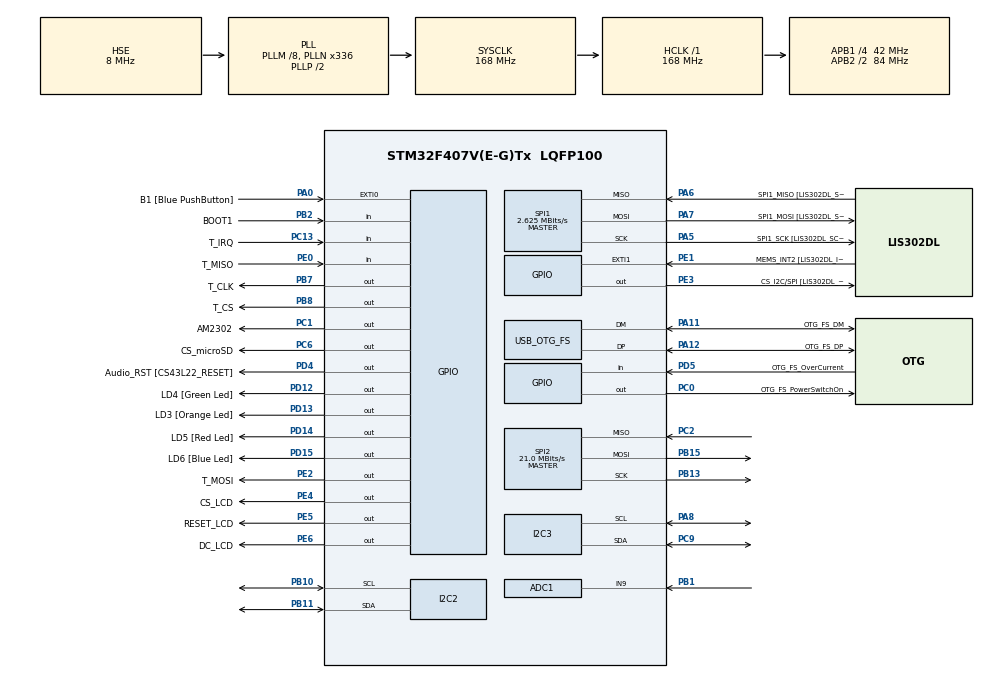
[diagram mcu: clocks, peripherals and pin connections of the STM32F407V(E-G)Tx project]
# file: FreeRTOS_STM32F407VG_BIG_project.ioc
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ADC1.Channel-6\#ChannelRegularConversion=ADC_CHANNEL_9
ADC1.NbrOfConversionFlag=1
ADC1.Rank-6\#ChannelRegularConversion=1
ADC1.SamplingTime-6\#ChannelRegularConversion=ADC_SAMPLETIME_3CYCLES
ADC1.master=1
Dma.Request0=SPI2_TX
Dma.SPI2_TX.0.Direction=DMA_MEMORY_TO_PERIPH
Dma.SPI2_TX.0.FIFOMode=DMA_FIFOMODE_DISABLE
Dma.SPI2_TX.0.Instance=DMA1_Stream4
Dma.SPI2_TX.0.MemDataAlignment=DMA_MDATAALIGN_BYTE
Dma.SPI2_TX.0.MemInc=DMA_MINC_ENABLE
Dma.SPI2_TX.0.Mode=DMA_CIRCULAR
Dma.SPI2_TX.0.PeriphDataAlignment=DMA_PDATAALIGN_BYTE
Dma.SPI2_TX.0.PeriphInc=DMA_PINC_DISABLE
Dma.SPI2_TX.0.Priority=DMA_PRIORITY_LOW
FATFS._CODE_PAGE=850
FATFS._MAX_SS=4096
FATFS._USE_LFN=2
FREERTOS.Queues01=UARTQueue,10,QUEUE_t,0,Static,UARTQueueBuffer,UARTQueueControlBlock;LCDQueue,1,LCDQUEUE,0,Static,LCDQueueBuffer,LCDQueueControlBlock;BME280_Queue,2,BME280QUEUE,0,Static,BME280_QueueBuffer,BME280_QueueControlBlock;MPU6050_Acc_Queue,1,MPU6050ACCQUEUE,0,Static,MPU6050_QueueBuffer,MPU6050_QueueControlBlock;MPU6050_Gyro_Queue,1,MPU6050GYROQUEUE,0,Static,MPU6050_Gyro_QueueBuffer,MPU6050_Gyro_QueueControlBlock;MPU6050_Temp_Queue,1,MPU6050TEMPQUEUE,0,Static,MPU6050_Temp_QueueBuffer,MPU6050_Temp_QueueControlBlock;MS5611_mag_Queue,1,MS5611QUEUE,0,Static,MS5611_mag_QueueBuffer,MS5611_mag_QueueControlBlock;ADC_Queue,3,ADCQUEUE,0,Static,ADC_QueueBuffer,ADC_QueueControlBlock
FREERTOS.Tasks01=defaultTask,24,128,StartDefaultTask,Default,NULL,Static,defaultTaskBuffer,defaultTaskControlBlock;RTC,8,500,Start_RTC,Default,NULL,Static,Blue_LED_BlinkBuffer,Blue_LED_BlinkControlBlock;Show_Resources,8,500,Start_Show_Resources,Default,NULL,Static,Show_ResourcesBuffer,Show_ResourcesControlBlock;UART_Task,8,500,Start_UART_Task,Default,NULL,Static,UART_TaskBuffer,UART_TaskControlBlock;bme280,8,550,Start_bme280,Default,NULL,Static,bme280Buffer,bme280ControlBlock;AM2302,8,500,Start_AM2302,Default,NULL,Static,AM2302Buffer,AM2302ControlBlock;SD_CARD,40,500,Start_SD_CARD,Default,NULL,Static,SD_CARDBuffer,SD_CARDControlBlock;LCD,8,1500,Start_LCD,Default,NULL,Static,LCDBuffer,LCDControlBlock;LCD_touchscreen,8,128,Start_LCD_touchscreen,Default,NULL,Static,LCD_touchscreenBuffer,LCD_touchscreenControlBlock;MPU6050,8,500,Start_MPU6050,Default,NULL,Static,MPU6050Buffer,MPU6050ControlBlock;MS5611,8,256,Start_MS5611,Default,NULL,Static,MS5611Buffer,MS5611ControlBlock;ADC,8,500,Start_ADC,Default,NULL,Static,ADCBuffer,ADCControlBlock
FREERTOS.configGENERATE_RUN_TIME_STATS=1
FREERTOS.configTOTAL_HEAP_SIZE=16000
FREERTOS.configUSE_NEWLIB_REENTRANT=1
FREERTOS.configUSE_STATS_FORMATTING_FUNCTIONS=1
Mcu.Family=STM32F4
Mcu.Name=STM32F407V(E-G)Tx
Mcu.Package=LQFP100
NVIC.DMA1_Stream4_IRQn=true\:5\:0\:true\:false\:true\:true\:false\:true
NVIC.OTG_FS_IRQn=true\:5\:0\:false\:false\:true\:true\:true\:true
NVIC.PriorityGroup=NVIC_PRIORITYGROUP_4
NVIC.SPI2_IRQn=true\:5\:0\:false\:false\:true\:true\:true\:true
NVIC.TIM1_UP_TIM10_IRQn=true\:5\:0\:false\:false\:true\:false\:false\:true
NVIC.TIM2_IRQn=true\:5\:0\:false\:false\:true\:true\:true\:true
NVIC.TIM3_IRQn=true\:5\:0\:false\:false\:true\:true\:true\:true
NVIC.TIM8_TRG_COM_TIM14_IRQn=true\:15\:0\:false\:false\:true\:false\:false\:true
NVIC.TimeBase=TIM8_TRG_COM_TIM14_IRQn
NVIC.TimeBaseIP=TIM14
PA0-WKUP.GPIO_Label=B1 [Blue PushButton]
PA0-WKUP.GPIO_ModeDefaultEXTI=GPIO_MODE_EVT_RISING
PA0-WKUP.GPIO_PuPd=GPIO_NOPULL
PA0-WKUP.Signal=GPXTI0
PA10.GPIO_Label=OTG_FS_ID
PA10.GPIO_Mode=GPIO_MODE_AF_PP
PA10.GPIO_PuPd=GPIO_NOPULL
PA10.GPIO_Speed=GPIO_SPEED_FREQ_LOW
PA10.Signal=USB_OTG_FS_ID
PA11.GPIO_Label=OTG_FS_DM
PA11.GPIO_Mode=GPIO_MODE_AF_PP
PA11.GPIO_PuPd=GPIO_NOPULL
PA11.GPIO_Speed=GPIO_SPEED_FREQ_LOW
PA11.Mode=Device_Only
PA11.Signal=USB_OTG_FS_DM
PA12.GPIO_Label=OTG_FS_DP
PA12.GPIO_Mode=GPIO_MODE_AF_PP
PA12.GPIO_PuPd=GPIO_NOPULL
PA12.GPIO_Speed=GPIO_SPEED_FREQ_LOW
PA12.Mode=Device_Only
PA12.Signal=USB_OTG_FS_DP
PA13.GPIO_Label=SWDIO
PA13.Mode=Serial_Wire
PA13.Signal=SYS_JTMS-SWDIO
PA14.GPIO_Label=SWCLK
PA14.Mode=Serial_Wire
PA14.Signal=SYS_JTCK-SWCLK
PA4.GPIO_Label=I2S3_WS [CS43L22_LRCK]
PA4.GPIO_Mode=GPIO_MODE_AF_PP
PA4.GPIO_PuPd=GPIO_NOPULL
PA4.GPIO_Speed=GPIO_SPEED_FREQ_LOW
PA4.Signal=I2S3_WS
PA5.GPIO_Label=SPI1_SCK [LIS302DL_SCL/SPC]
PA5.GPIO_Mode=GPIO_MODE_AF_PP
PA5.GPIO_PuPd=GPIO_NOPULL
PA5.GPIO_Speed=GPIO_SPEED_FREQ_HIGH
PA5.Mode=Full_Duplex_Master
PA5.Signal=SPI1_SCK
PA6.GPIO_Label=SPI1_MISO [LIS302DL_SDO]
PA6.GPIO_Mode=GPIO_MODE_AF_PP
PA6.GPIO_PuPd=GPIO_NOPULL
PA6.GPIO_Speed=GPIO_SPEED_FREQ_HIGH
PA6.Mode=Full_Duplex_Master
PA6.Signal=SPI1_MISO
PA7.GPIO_Label=SPI1_MOSI [LIS302DL_SDA/SDI/SDO]
PA7.GPIO_Mode=GPIO_MODE_AF_PP
PA7.GPIO_PuPd=GPIO_NOPULL
PA7.GPIO_Speed=GPIO_SPEED_FREQ_HIGH
PA7.Mode=Full_Duplex_Master
PA7.Signal=SPI1_MOSI
PA8.Mode=I2C
PA8.Signal=I2C3_SCL
PA9.GPIO_Label=VBUS_FS
PA9.GPIO_Mode=GPIO_MODE_INPUT
PA9.GPIO_PuPd=GPIO_NOPULL
PA9.Signal=USB_OTG_FS_VBUS
PB1.Signal=ADCx_IN9
PB10.Mode=I2C
PB10.Signal=I2C2_SCL
PB11.Mode=I2C
PB11.Signal=I2C2_SDA
PB13.Mode=Full_Duplex_Master
PB13.Signal=SPI2_SCK
PB15.Mode=Full_Duplex_Master
PB15.Signal=SPI2_MOSI
PB2.GPIO_Label=BOOT1
PB2.GPIO_Mode=GPIO_MODE_INPUT
PB2.GPIO_PuPd=GPIO_NOPULL
PB2.Signal=GPIO_Input
PB3.GPIO_Label=SWO
PB3.Signal=SYS_JTDO-SWO
PB6.GPIO_Label=Audio_SCL [CS43L22_SCL]
PB6.GPIO_Mode=GPIO_MODE_AF_OD
PB6.GPIO_Pu=GPIO_PULLUP
PB6.GPIO_PuPd=GPIO_NOPULL
PB6.GPIO_Speed=GPIO_SPEED_FREQ_LOW
PB6.Signal=I2C1_SCL
PB7.GPIO_Label=T_CLK
PB7.GPIO_Speed=GPIO_SPEED_FREQ_VERY_HIGH
PB7.Signal=GPIO_Output
PB8.GPIO_Label=T_CS
PB8.GPIO_Speed=GPIO_SPEED_FREQ_VERY_HIGH
PB8.Signal=GPIO_Output
PB9.GPIO_Label=Audio_SDA [CS43L22_SDA]
PB9.GPIO_Mode=GPIO_MODE_AF_OD
PB9.GPIO_Pu=GPIO_PULLUP
PB9.GPIO_PuPd=GPIO_NOPULL
PB9.GPIO_Speed=GPIO_SPEED_FREQ_LOW
PB9.Signal=I2C1_SDA
PC0.GPIO_Label=OTG_FS_PowerSwitchOn
PC0.GPIO_PuPd=GPIO_NOPULL
PC0.GPIO_Speed=GPIO_SPEED_FREQ_LOW
PC0.PinState=GPIO_PIN_SET
PC0.Signal=GPIO_Output
PC1.GPIO_Label=AM2302
PC1.Signal=GPIO_Output
PC10.GPIO_Label=I2S3_SCK [CS43L22_SCLK]
PC10.GPIO_Mode=GPIO_MODE_AF_PP
PC10.GPIO_PuPd=GPIO_NOPULL
PC10.GPIO_Speed=GPIO_SPEED_FREQ_LOW
PC10.Signal=I2S3_CK
PC12.GPIO_Label=I2S3_SD [CS43L22_SDIN]
PC12.GPIO_Mode=GPIO_MODE_AF_PP
PC12.GPIO_PuPd=GPIO_NOPULL
PC12.GPIO_Speed=GPIO_SPEED_FREQ_LOW
PC12.Signal=I2S3_SD
PC13-ANTI_TAMP.GPIO_Label=T_IRQ
PC13-ANTI_TAMP.Signal=GPIO_Input
PC14-OSC32_IN.GPIO_Label=PC14-OSC32_IN
PC14-OSC32_IN.Mode=LSE-External-Oscillator
PC14-OSC32_IN.Signal=RCC_OSC32_IN
PC15-OSC32_OUT.GPIO_Label=PC15-OSC32_OUT
PC15-OSC32_OUT.Mode=LSE-External-Oscillator
PC15-OSC32_OUT.Signal=RCC_OSC32_OUT
PC2.Mode=Full_Duplex_Master
PC2.Signal=SPI2_MISO
PC3.GPIO_Label=PDM_OUT [MP45DT02_DOUT]
PC3.GPIO_Mode=GPIO_MODE_AF_PP
PC3.GPIO_PuPd=GPIO_NOPULL
PC3.GPIO_Speed=GPIO_SPEED_FREQ_LOW
PC3.Signal=I2S2_SD
PC6.GPIO_Label=CS_microSD
PC6.GPIO_Speed=GPIO_SPEED_FREQ_HIGH
PC6.Signal=GPIO_Output
PC7.GPIO_Label=I2S3_MCK [CS43L22_MCLK]
PC7.GPIO_Mode=GPIO_MODE_AF_PP
PC7.GPIO_PuPd=GPIO_NOPULL
PC7.GPIO_Speed=GPIO_SPEED_FREQ_LOW
PC7.Signal=I2S3_MCK
PC9.Mode=I2C
PC9.Signal=I2C3_SDA
PD12.GPIO_Label=LD4 [Green Led]
PD12.GPIO_PuPd=GPIO_NOPULL
PD12.GPIO_Speed=GPIO_SPEED_FREQ_LOW
PD12.Signal=GPIO_Output
PD13.GPIO_Label=LD3 [Orange Led]
PD13.GPIO_PuPd=GPIO_NOPULL
PD13.GPIO_Speed=GPIO_SPEED_FREQ_LOW
PD13.Signal=GPIO_Output
PD14.GPIO_Label=LD5 [Red Led]
PD14.GPIO_PuPd=GPIO_NOPULL
PD14.GPIO_Speed=GPIO_SPEED_FREQ_LOW
PD14.Signal=GPIO_Output
PD15.GPIO_Label=LD6 [Blue Led]
PD15.GPIO_PuPd=GPIO_NOPULL
PD15.GPIO_Speed=GPIO_SPEED_FREQ_LOW
PD15.Signal=GPIO_Output
PD4.GPIO_Label=Audio_RST [CS43L22_RESET]
PD4.GPIO_PuPd=GPIO_NOPULL
PD4.GPIO_Speed=GPIO_SPEED_FREQ_LOW
PD4.Signal=GPIO_Output
PD5.GPIO_Label=OTG_FS_OverCurrent
PD5.GPIO_Mode=GPIO_MODE_INPUT
PD5.GPIO_PuPd=GPIO_NOPULL
PD5.Signal=GPIO_Input
PE0.GPIO_Label=T_MISO
PE0.Signal=GPIO_Input
PE1.GPIO_Label=MEMS_INT2 [LIS302DL_INT2]
PE1.GPIO_ModeDefaultEXTI=GPIO_MODE_EVT_RISING
PE1.GPIO_PuPd=GPIO_NOPULL
PE1.Signal=GPXTI1
PE2.GPIO_Label=T_MOSI
PE2.Signal=GPIO_Output
PE3.GPIO_Label=CS_I2C/SPI [LIS302DL_CS_I2C/SPI]
PE3.GPIO_PuPd=GPIO_NOPULL
PE3.GPIO_Speed=GPIO_SPEED_FREQ_LOW
PE3.Signal=GPIO_Output
PE4.GPIO_Label=CS_LCD
PE4.Signal=GPIO_Output
PE5.GPIO_Label=RESET_LCD
PE5.GPIO_Speed=GPIO_SPEED_FREQ_VERY_HIGH
PE5.Signal=GPIO_Output
PE6.GPIO_Label=DC_LCD
PE6.GPIO_Speed=GPIO_SPEED_FREQ_VERY_HIGH
PE6.Signal=GPIO_Output
PH0-OSC_IN.GPIO_Label=PH0-OSC_IN
PH0-OSC_IN.Mode=HSE-External-Oscillator
PH0-OSC_IN.Signal=RCC_OSC_IN
PH1-OSC_OUT.GPIO_Label=PH1-OSC_OUT
PH1-OSC_OUT.Mode=HSE-External-Oscillator
PH1-OSC_OUT.Signal=RCC_OSC_OUT
ProjectManager.HeapSize=0x800
ProjectManager.StackSize=0x900
ProjectManager.TargetToolchain=STM32CubeIDE
RCC.48MHZClocksFreq_Value=48000000
RCC.AHBFreq_Value=168000000
RCC.APB1CLKDivider=RCC_HCLK_DIV4
RCC.APB1Freq_Value=42000000
RCC.APB1TimFreq_Value=84000000
RCC.APB2CLKDivider=RCC_HCLK_DIV2
RCC.APB2Freq_Value=84000000
RCC.APB2TimFreq_Value=168000000
RCC.CortexFreq_Value=168000000
RCC.HCLKFreq_Value=168000000
RCC.HSE_VALUE=8000000
RCC.HSI_VALUE=16000000
RCC.PLLM=8
RCC.PLLN=336
RCC.PLLQ=7
RCC.RCC_RTC_Clock_Source=RCC_RTCCLKSOURCE_LSE
RCC.RCC_RTC_Clock_SourceVirtual=RCC_RTCCLKSOURCE_LSE
RCC.SYSCLKFreq_VALUE=168000000
RCC.SYSCLKSource=RCC_SYSCLKSOURCE_PLLCLK
RCC.VCOOutputFreq_Value=336000000
RTC.Alarm=RTC_ALARM_A
RTC.AlarmDateWeekDaySel=RTC_ALARMDATEWEEKDAYSEL_WEEKDAY
RTC.Date=28
RTC.Hours=23
RTC.Minutes=59
RTC.Month=RTC_MONTH_DECEMBER
RTC.Seconds=45
RTC.Seconds_A=10
RTC.StoreOperation=RTC_STOREOPERATION_RESET
RTC.WeekDay=RTC_WEEKDAY_TUESDAY
SH.ADCx_IN9.0=ADC1_IN9,IN9
SPI1.BaudRatePrescaler=SPI_BAUDRATEPRESCALER_32
SPI1.CalculateBaudRate=2.625 MBits/s
SPI1.Direction=SPI_DIRECTION_2LINES
SPI1.Mode=SPI_MODE_MASTER
SPI1.VirtualType=VM_MASTER
SPI2.CalculateBaudRate=21.0 MBits/s
SPI2.Direction=SPI_DIRECTION_2LINES
SPI2.Mode=SPI_MODE_MASTER
SPI2.VirtualType=VM_MASTER
TIM1.Period=10000
TIM1.Prescaler=16800-1
TIM1.TIM_MasterOutputTrigger=TIM_TRGO_UPDATE
TIM10.AutoReloadPreload=TIM_AUTORELOAD_PRELOAD_ENABLE
TIM10.Period=10-1
TIM10.Prescaler=168-1
TIM2.AutoReloadPreload=TIM_AUTORELOAD_PRELOAD_DISABLE
TIM2.Period=10
TIM2.Prescaler=10
TIM3.AutoReloadPreload=TIM_AUTORELOAD_PRELOAD_ENABLE
TIM3.Period=10
TIM3.Prescaler=839
USB_DEVICE.CLASS_NAME_FS=CDC
USB_DEVICE.VirtualMode-CDC_FS=Cdc
USB_DEVICE.VirtualModeFS=Cdc_FS
USB_OTG_FS.VirtualMode=Device_Only
VP_FATFS_VS_Generic.Mode=User_defined
VP_FREERTOS_VS_CMSIS_V2.Mode=CMSIS_V2
VP_RNG_VS_RNG.Mode=RNG_Activate
VP_RTC_VS_RTC_Activate.Mode=RTC_Enabled
VP_RTC_VS_RTC_Alarm_A_Intern.Mode=Alarm A
VP_RTC_VS_RTC_Calendar.Mode=RTC_Calendar
VP_SYS_VS_tim14.Mode=TIM14
VP_TIM10_VS_ClockSourceINT.Mode=Enable_Timer
VP_TIM1_VS_ClockSourceINT.Mode=Internal
VP_TIM2_VS_ClockSourceINT.Mode=Internal
VP_TIM3_VS_ClockSourceINT.Mode=Internal
VP_USB_DEVICE_VS_USB_DEVICE_CDC_FS.Mode=CDC_FS
board=STM32F407G-DISC1

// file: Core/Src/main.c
/* USER CODE BEGIN Header */
/**
  ******************************************************************************
  * @file           : main.c
  * @brief          : Main program body
  ******************************************************************************
  * @attention
  *
  * <h2><center>&copy; Copyright (c) 2021 STMicroelectronics.
  * All rights reserved.</center></h2>
  *
  * This software component is licensed by ST under Ultimate Liberty license
  * SLA0044, the "License"; You may not use this file except in compliance with
  * the License. You may obtain a copy of the License at:
  *                             www.st.com/SLA0044
  *
  ******************************************************************************
  */
/* USER CODE END Header */
#include "main.h"
#include "cmsis_os.h"
#include "fatfs.h"
#include "usb_device.h"
#include "usb_device.h"

/* USER CODE BEGIN Includes */
#include "string.h"
#include "usbd_cdc_if.h"
#include "task.h"
#include <stdio.h>
#include <stdbool.h>
#include <SD_Card/File_Handling_RTOS.h>

// Sensors
#include "sensors/BME280/bme280_defs.h"
#include "sensors/BME280/bme280.h"

// SD
#include "LCD/spi_ili9341.h"
#include "LCD/ILI9341_Touchscreen.h"

#include "sensors/MEMS/mpu6050.h"

#include "sensors/MEMS/ms5611.h"

/* USER CODE END Includes */

typedef StaticTask_t osStaticThreadDef_t;
typedef StaticQueue_t osStaticMessageQDef_t;
/* USER CODE BEGIN PTD */
typedef struct 							// Queue for UARD
{
	char Buf[1024];
}QUEUE_t;

typedef struct							// Queue for Touch LCD
{
	char buff[100];
}LCDQUEUE;

typedef struct
{
	char bme280_temperature_and_humidity[20];
}BME280QUEUE;

typedef struct
{
	char mpu6050_acc_x_y_z[30];
}MPU6050ACCQUEUE;

typedef struct
{
	char mpu6050_gyro_x_y_z[30];
}MPU6050GYROQUEUE;

typedef struct
{
	char mpu6050_temp[10];
}MPU6050TEMPQUEUE;

typedef struct
{
	char MS5611_mag_x_y_z_temp_and_pressure[30];
}MS5611QUEUE;

typedef struct
{
	char ADC_value_and_voltage[30];
}ADCQUEUE;

volatile unsigned long ulHighFreqebcyTimerTicks;		// This variable using for calculate how many time all tasks was running.
char str_management_memory_str[1000] = {0};
int freemem = 0;

uint32_t tim_val = 0;

// For SD works (use in fatfs_sd.c file)
volatile uint8_t FatFsCnt = 0;
volatile uint8_t Timer1, Timer2;

// LCD //////////////////////////////////
extern uint16_t TFT9341_WIDTH;
extern uint16_t TFT9341_HEIGHT;
// LCD DMA
uint8_t dma_spi_fl=0;
uint32_t dma_spi_cnt=1;
////////////////////////////////////////
// MS5611 sensor P and T
extern uint32_t raw_pressure, raw_temperature;

/* USER CODE END PTD */

ADC_HandleTypeDef hadc1;

I2C_HandleTypeDef hi2c2;
I2C_HandleTypeDef hi2c3;

RNG_HandleTypeDef hrng;

RTC_HandleTypeDef hrtc;

SPI_HandleTypeDef hspi1;
SPI_HandleTypeDef hspi2;
DMA_HandleTypeDef hdma_spi2_tx;

TIM_HandleTypeDef htim1;
TIM_HandleTypeDef htim2;
TIM_HandleTypeDef htim3;
TIM_HandleTypeDef htim10;

/* Definitions for defaultTask */
osThreadId_t defaultTaskHandle;
uint32_t defaultTaskBuffer[ 128 ];
osStaticThreadDef_t defaultTaskControlBlock;
const osThreadAttr_t defaultTask_attributes = {
  .name = "defaultTask",
  .cb_mem = &defaultTaskControlBlock,
  .cb_size = sizeof(defaultTaskControlBlock),
  .stack_mem = &defaultTaskBuffer[0],
  .stack_size = sizeof(defaultTaskBuffer),
  .priority = (osPriority_t) osPriorityNormal,
};
/* Definitions for RTC */
osThreadId_t RTCHandle;
uint32_t Blue_LED_BlinkBuffer[ 500 ];
osStaticThreadDef_t Blue_LED_BlinkControlBlock;
const osThreadAttr_t RTC_attributes = {
  .name = "RTC",
  .cb_mem = &Blue_LED_BlinkControlBlock,
  .cb_size = sizeof(Blue_LED_BlinkControlBlock),
  .stack_mem = &Blue_LED_BlinkBuffer[0],
  .stack_size = sizeof(Blue_LED_BlinkBuffer),
  .priority = (osPriority_t) osPriorityLow,
};
/* Definitions for Show_Resources */
osThreadId_t Show_ResourcesHandle;
uint32_t Show_ResourcesBuffer[ 500 ];
osStaticThreadDef_t Show_ResourcesControlBlock;
const osThreadAttr_t Show_Resources_attributes = {
  .name = "Show_Resources",
  .cb_mem = &Show_ResourcesControlBlock,
  .cb_size = sizeof(Show_ResourcesControlBlock),
  .stack_mem = &Show_ResourcesBuffer[0],
  .stack_size = sizeof(Show_ResourcesBuffer),
  .priority = (osPriority_t) osPriorityLow,
};
/* Definitions for UART_Task */
osThreadId_t UART_TaskHandle;
uint32_t UART_TaskBuffer[ 500 ];
osStaticThreadDef_t UART_TaskControlBlock;
const osThreadAttr_t UART_Task_attributes = {
  .name = "UART_Task",
  .cb_mem = &UART_TaskControlBlock,
  .cb_size = sizeof(UART_TaskControlBlock),
  .stack_mem = &UART_TaskBuffer[0],
  .stack_size = sizeof(UART_TaskBuffer),
  .priority = (osPriority_t) osPriorityLow,
};
/* Definitions for bme280 */
osThreadId_t bme280Handle;
uint32_t bme280Buffer[ 550 ];
osStaticThreadDef_t bme280ControlBlock;
const osThreadAttr_t bme280_attributes = {
  .name = "bme280",
  .cb_mem = &bme280ControlBlock,
  .cb_size = sizeof(bme280ControlBlock),
  .stack_mem = &bme280Buffer[0],
  .stack_size = sizeof(bme280Buffer),
  .priority = (osPriority_t) osPriorityLow,
};
/* Definitions for AM2302 */
osThreadId_t AM2302Handle;
uint32_t AM2302Buffer[ 500 ];
osStaticThreadDef_t AM2302ControlBlock;
const osThreadAttr_t AM2302_attributes = {
  .name = "AM2302",
  .cb_mem = &AM2302ControlBlock,
  .cb_size = sizeof(AM2302ControlBlock),
  .stack_mem = &AM2302Buffer[0],
  .stack_size = sizeof(AM2302Buffer),
  .priority = (osPriority_t) osPriorityLow,
};
/* Definitions for SD_CARD */
osThreadId_t SD_CARDHandle;
uint32_t SD_CARDBuffer[ 500 ];
osStaticThreadDef_t SD_CARDControlBlock;
const osThreadAttr_t SD_CARD_attributes = {
  .name = "SD_CARD",
  .cb_mem = &SD_CARDControlBlock,
  .cb_size = sizeof(SD_CARDControlBlock),
  .stack_mem = &SD_CARDBuffer[0],
  .stack_size = sizeof(SD_CARDBuffer),
  .priority = (osPriority_t) osPriorityHigh,
};
/* Definitions for LCD */
osThreadId_t LCDHandle;
uint32_t LCDBuffer[ 1500 ];
osStaticThreadDef_t LCDControlBlock;
const osThreadAttr_t LCD_attributes = {
  .name = "LCD",
  .cb_mem = &LCDControlBlock,
  .cb_size = sizeof(LCDControlBlock),
  .stack_mem = &LCDBuffer[0],
  .stack_size = sizeof(LCDBuffer),
  .priority = (osPriority_t) osPriorityLow,
};
/* Definitions for LCD_touchscreen */
osThreadId_t LCD_touchscreenHandle;
uint32_t LCD_touchscreenBuffer[ 128 ];
osStaticThreadDef_t LCD_touchscreenControlBlock;
const osThreadAttr_t LCD_touchscreen_attributes = {
  .name = "LCD_touchscreen",
  .cb_mem = &LCD_touchscreenControlBlock,
  .cb_size = sizeof(LCD_touchscreenControlBlock),
  .stack_mem = &LCD_touchscreenBuffer[0],
  .stack_size = sizeof(LCD_touchscreenBuffer),
  .priority = (osPriority_t) osPriorityLow,
};
/* Definitions for MPU6050 */
osThreadId_t MPU6050Handle;
uint32_t MPU6050Buffer[ 500 ];
osStaticThreadDef_t MPU6050ControlBlock;
const osThreadAttr_t MPU6050_attributes = {
  .name = "MPU6050",
  .cb_mem = &MPU6050ControlBlock,
  .cb_size = sizeof(MPU6050ControlBlock),
  .stack_mem = &MPU6050Buffer[0],
  .stack_size = sizeof(MPU6050Buffer),
  .priority = (osPriority_t) osPriorityLow,
};
/* Definitions for MS5611 */
osThreadId_t MS5611Handle;
uint32_t MS5611Buffer[ 256 ];
osStaticThreadDef_t MS5611ControlBlock;
const osThreadAttr_t MS5611_attributes = {
  .name = "MS5611",
  .cb_mem = &MS5611ControlBlock,
  .cb_size = sizeof(MS5611ControlBlock),
  .stack_mem = &MS5611Buffer[0],
  .stack_size = sizeof(MS5611Buffer),
  .priority = (osPriority_t) osPriorityLow,
};
/* Definitions for ADC */
osThreadId_t ADCHandle;
uint32_t ADCBuffer[ 500 ];
osStaticThreadDef_t ADCControlBlock;
const osThreadAttr_t ADC_attributes = {
  .name = "ADC",
  .cb_mem = &ADCControlBlock,
  .cb_size = sizeof(ADCControlBlock),
  .stack_mem = &ADCBuffer[0],
  .stack_size = sizeof(ADCBuffer),
  .priority = (osPriority_t) osPriorityLow,
};
/* Definitions for UARTQueue */
osMessageQueueId_t UARTQueueHandle;
uint8_t UARTQueueBuffer[ 10 * sizeof( QUEUE_t ) ];
osStaticMessageQDef_t UARTQueueControlBlock;
const osMessageQueueAttr_t UARTQueue_attributes = {
  .name = "UARTQueue",
  .cb_mem = &UARTQueueControlBlock,
  .cb_size = sizeof(UARTQueueControlBlock),
  .mq_mem = &UARTQueueBuffer,
  .mq_size = sizeof(UARTQueueBuffer)
};
/* Definitions for LCDQueue */
osMessageQueueId_t LCDQueueHandle;
uint8_t LCDQueueBuffer[ 1 * sizeof( LCDQUEUE ) ];
osStaticMessageQDef_t LCDQueueControlBlock;
const osMessageQueueAttr_t LCDQueue_attributes = {
  .name = "LCDQueue",
  .cb_mem = &LCDQueueControlBlock,
  .cb_size = sizeof(LCDQueueControlBlock),
  .mq_mem = &LCDQueueBuffer,
  .mq_size = sizeof(LCDQueueBuffer)
};
/* Definitions for BME280_Queue */
osMessageQueueId_t BME280_QueueHandle;
uint8_t BME280_QueueBuffer[ 2 * sizeof( BME280QUEUE ) ];
osStaticMessageQDef_t BME280_QueueControlBlock;
const osMessageQueueAttr_t BME280_Queue_attributes = {
  .name = "BME280_Queue",
  .cb_mem = &BME280_QueueControlBlock,
  .cb_size = sizeof(BME280_QueueControlBlock),
  .mq_mem = &BME280_QueueBuffer,
  .mq_size = sizeof(BME280_QueueBuffer)
};
/* Definitions for MPU6050_Acc_Queue */
osMessageQueueId_t MPU6050_Acc_QueueHandle;
uint8_t MPU6050_QueueBuffer[ 1 * sizeof( MPU6050ACCQUEUE ) ];
osStaticMessageQDef_t MPU6050_QueueControlBlock;
const osMessageQueueAttr_t MPU6050_Acc_Queue_attributes = {
  .name = "MPU6050_Acc_Queue",
  .cb_mem = &MPU6050_QueueControlBlock,
  .cb_size = sizeof(MPU6050_QueueControlBlock),
  .mq_mem = &MPU6050_QueueBuffer,
  .mq_size = sizeof(MPU6050_QueueBuffer)
};
/* Definitions for MPU6050_Gyro_Queue */
osMessageQueueId_t MPU6050_Gyro_QueueHandle;
uint8_t MPU6050_Gyro_QueueBuffer[ 1 * sizeof( MPU6050GYROQUEUE ) ];
osStaticMessageQDef_t MPU6050_Gyro_QueueControlBlock;
const osMessageQueueAttr_t MPU6050_Gyro_Queue_attributes = {
  .name = "MPU6050_Gyro_Queue",
  .cb_mem = &MPU6050_Gyro_QueueControlBlock,
  .cb_size = sizeof(MPU6050_Gyro_QueueControlBlock),
  .mq_mem = &MPU6050_Gyro_QueueBuffer,
  .mq_size = sizeof(MPU6050_Gyro_QueueBuffer)
};
/* Definitions for MPU6050_Temp_Queue */
osMessageQueueId_t MPU6050_Temp_QueueHandle;
uint8_t MPU6050_Temp_QueueBuffer[ 1 * sizeof( MPU6050TEMPQUEUE ) ];
osStaticMessageQDef_t MPU6050_Temp_QueueControlBlock;
const osMessageQueueAttr_t MPU6050_Temp_Queue_attributes = {
  .name = "MPU6050_Temp_Queue",
  .cb_mem = &MPU6050_Temp_QueueControlBlock,
  .cb_size = sizeof(MPU6050_Temp_QueueControlBlock),
  .mq_mem = &MPU6050_Temp_QueueBuffer,
  .mq_size = sizeof(MPU6050_Temp_QueueBuffer)
};
/* Definitions for MS5611_mag_Queue */
osMessageQueueId_t MS5611_mag_QueueHandle;
uint8_t MS5611_mag_QueueBuffer[ 1 * sizeof( MS5611QUEUE ) ];
osStaticMessageQDef_t MS5611_mag_QueueControlBlock;
const osMessageQueueAttr_t MS5611_mag_Queue_attributes = {
  .name = "MS5611_mag_Queue",
  .cb_mem = &MS5611_mag_QueueControlBlock,
  .cb_size = sizeof(MS5611_mag_QueueControlBlock),
  .mq_mem = &MS5611_mag_QueueBuffer,
  .mq_size = sizeof(MS5611_mag_QueueBuffer)
};
/* Definitions for ADC_Queue */
osMessageQueueId_t ADC_QueueHandle;
uint8_t ADC_QueueBuffer[ 3 * sizeof( ADCQUEUE ) ];
osStaticMessageQDef_t ADC_QueueControlBlock;
const osMessageQueueAttr_t ADC_Queue_attributes = {
  .name = "ADC_Queue",
  .cb_mem = &ADC_QueueControlBlock,
  .cb_size = sizeof(ADC_QueueControlBlock),
  .mq_mem = &ADC_QueueBuffer,
  .mq_size = sizeof(ADC_QueueBuffer)
};
/* USER CODE BEGIN PV */

// BME280 part /////////////////////////////////////////////////////////////////////////////////////
struct bme280_dev dev;
struct bme280_data comp_data;
int8_t rslt;

int8_t init_bme280(void);
void bme280_measure(void);

//----------------------------------------------------------------------------------------
int8_t user_i2c_read(uint8_t id, uint8_t reg_addr, uint8_t *data, uint16_t len)
{
  if(HAL_I2C_Master_Transmit(&hi2c3, (id << 1), &reg_addr, 1, 10) != HAL_OK) return -1;
  if(HAL_I2C_Master_Receive(&hi2c3, (id << 1) | 0x01, data, len, 10) != HAL_OK) return -1;

  return 0;
}
//----------------------------------------------------------------------------------------
void user_delay_ms(uint32_t period)
{
  HAL_Delay(period);
}
//----------------------------------------------------------------------------------------
int8_t user_i2c_write(uint8_t id, uint8_t reg_addr, uint8_t *data, uint16_t len)
{
  int8_t *buf;
  buf = malloc(len +1);
  buf[0] = reg_addr;
  memcpy(buf +1, data, len);

  if(HAL_I2C_Master_Transmit(&hi2c3, (id << 1), (uint8_t*)buf, len + 1, HAL_MAX_DELAY) != HAL_OK) return -1;

  free(buf);
  return 0;
}
// End BME280 part/////////////////////////////////////////////////////////////////////////////////////

// ---------------------------------------------------------------------------------
// Function for generate dalay more than 10 us (using for AM2302 T and H sensor)
bool delay_us(uint16_t us)
{
	__HAL_TIM_SET_COUNTER(&htim10, 0);
	tim_val = us/10;
	HAL_TIM_Base_Start_IT(&htim10);
	while(tim_val != 0)
	{

	}
	HAL_TIM_Base_Stop_IT(&htim10);
	tim_val = 0;
	int s = 99;
	return true;
}
// ---------------------------------------------------------------------------------
// For DMA SPI2 (LCD)
void HAL_SPI_TxCpltCallback(SPI_HandleTypeDef *hspi)
{
	if(hspi == &hspi2)
	{
	    dma_spi_cnt--;
	    if(dma_spi_cnt==0)
	    {
	    	HAL_SPI_DMAStop(&hspi2);
	    	dma_spi_cnt=1;
	    	dma_spi_fl=1;
	    }
	}
}
// ---------------------------------------------------------------------------------
/* USER CODE END PV */

void SystemClock_Config(void);
static void MX_GPIO_Init(void);
static void MX_TIM3_Init(void);
static void MX_I2C3_Init(void);
static void MX_TIM2_Init(void);
static void MX_TIM10_Init(void);
static void MX_SPI1_Init(void);
static void MX_TIM1_Init(void);
static void MX_RTC_Init(void);
static void MX_SPI2_Init(void);
static void MX_DMA_Init(void);
static void MX_RNG_Init(void);
static void MX_I2C2_Init(void);
static void MX_ADC1_Init(void);
void StartDefaultTask(void *argument);
void Start_RTC(void *argument);
void Start_Show_Resources(void *argument);
void Start_UART_Task(void *argument);
void Start_bme280(void *argument);
void Start_AM2302(void *argument);
void Start_SD_CARD(void *argument);
void Start_LCD(void *argument);
void Start_LCD_touchscreen(void *argument);
void Start_MPU6050(void *argument);
void Start_MS5611(void *argument);
void Start_ADC(void *argument);

int main(void)
{

  /* MCU Configuration--------------------------------------------------------*/

  /* Reset of all peripherals, Initializes the Flash interface and the Systick. */
  HAL_Init();

  /* Configure the system clock */
  SystemClock_Config();

  /* Initialize all configured peripherals */
  MX_GPIO_Init();
  MX_TIM3_Init();
  MX_I2C3_Init();
  MX_TIM2_Init();
  MX_TIM10_Init();
  MX_SPI1_Init();
  MX_FATFS_Init();
  MX_TIM1_Init();
  MX_RTC_Init();
  MX_SPI2_Init();
  MX_DMA_Init();
  MX_RNG_Init();
  MX_I2C2_Init();
  MX_ADC1_Init();
  /* USER CODE BEGIN 2 */
  HAL_TIM_Base_Start_IT(&htim3);		//  This TIM3 using for calculate how many time all tasks was running.

  //HAL_TIM_Base_Start_IT(&htim2);
  //HAL_TIM_Base_Start_IT(&htim10);			// Using for generate us delays
  HAL_TIM_Base_Start_IT(&htim1);			// Blink Green LED

  /* IF LCD DOESN'T WORK !
  RIGHT IN RIGHT ORDER SPI2 AND DMA !!!!
  MX_DMA_Init();
  MX_SPI2_Init();
  */
  HAL_DMA_DeInit(&hdma_spi2_tx);
  HAL_SPI_DeInit(&hspi2);
  MX_DMA_Init();
  MX_SPI2_Init();

  /* USER CODE END 2 */

  /* Init scheduler */
  osKernelInitialize();

  /* Create the queue(s) */
  /* creation of UARTQueue */
  UARTQueueHandle = osMessageQueueNew (10, sizeof(QUEUE_t), &UARTQueue_attributes);

  /* creation of LCDQueue */
  LCDQueueHandle = osMessageQueueNew (1, sizeof(LCDQUEUE), &LCDQueue_attributes);

  /* creation of BME280_Queue */
  BME280_QueueHandle = osMessageQueueNew (2, sizeof(BME280QUEUE), &BME280_Queue_attributes);

  /* creation of MPU6050_Acc_Queue */
  MPU6050_Acc_QueueHandle = osMessageQueueNew (1, sizeof(MPU6050ACCQUEUE), &MPU6050_Acc_Queue_attributes);

  /* creation of MPU6050_Gyro_Queue */
  MPU6050_Gyro_QueueHandle = osMessageQueueNew (1, sizeof(MPU6050GYROQUEUE), &MPU6050_Gyro_Queue_attributes);

  /* creation of MPU6050_Temp_Queue */
  MPU6050_Temp_QueueHandle = osMessageQueueNew (1, sizeof(MPU6050TEMPQUEUE), &MPU6050_Temp_Queue_attributes);

  /* creation of MS5611_mag_Queue */
  MS5611_mag_QueueHandle = osMessageQueueNew (1, sizeof(MS5611QUEUE), &MS5611_mag_Queue_attributes);

  /* creation of ADC_Queue */
  ADC_QueueHandle = osMessageQueueNew (3, sizeof(ADCQUEUE), &ADC_Queue_attributes);

  /* Create the thread(s) */
  /* creation of defaultTask */
  defaultTaskHandle = osThreadNew(StartDefaultTask, NULL, &defaultTask_attributes);

  /* creation of RTC */
  RTCHandle = osThreadNew(Start_RTC, NULL, &RTC_attributes);

  /* creation of Show_Resources */
  Show_ResourcesHandle = osThreadNew(Start_Show_Resources, NULL, &Show_Resources_attributes);

  /* creation of UART_Task */
  UART_TaskHandle = osThreadNew(Start_UART_Task, NULL, &UART_Task_attributes);

  /* creation of bme280 */
  bme280Handle = osThreadNew(Start_bme280, NULL, &bme280_attributes);

  /* creation of AM2302 */
  AM2302Handle = osThreadNew(Start_AM2302, NULL, &AM2302_attributes);

  /* creation of SD_CARD */
  SD_CARDHandle = osThreadNew(Start_SD_CARD, NULL, &SD_CARD_attributes);

  /* creation of LCD */
  LCDHandle = osThreadNew(Start_LCD, NULL, &LCD_attributes);

  /* creation of LCD_touchscreen */
  LCD_touchscreenHandle = osThreadNew(Start_LCD_touchscreen, NULL, &LCD_touchscreen_attributes);

  /* creation of MPU6050 */
  MPU6050Handle = osThreadNew(Start_MPU6050, NULL, &MPU6050_attributes);

  /* creation of MS5611 */
  MS5611Handle = osThreadNew(Start_MS5611, NULL, &MS5611_attributes);

  /* creation of ADC */
  ADCHandle = osThreadNew(Start_ADC, NULL, &ADC_attributes);

  /* Start scheduler */
  osKernelStart();

  /* We should never get here as control is now taken by the scheduler */
  /* Infinite loop */
  while (1)
  {

  }
}

void SystemClock_Config(void)
{
  RCC_OscInitTypeDef RCC_OscInitStruct = {0};
  RCC_ClkInitTypeDef RCC_ClkInitStruct = {0};

  /** Configure the main internal regulator output voltage
  */
  __HAL_RCC_PWR_CLK_ENABLE();
  __HAL_PWR_VOLTAGESCALING_CONFIG(PWR_REGULATOR_VOLTAGE_SCALE1);
  /** Initializes the RCC Oscillators according to the specified parameters
  * in the RCC_OscInitTypeDef structure.
  */
  RCC_OscInitStruct.OscillatorType = RCC_OSCILLATORTYPE_HSE|RCC_OSCILLATORTYPE_LSE;
  RCC_OscInitStruct.HSEState = RCC_HSE_ON;
  RCC_OscInitStruct.LSEState = RCC_LSE_ON;
  RCC_OscInitStruct.PLL.PLLState = RCC_PLL_ON;
  RCC_OscInitStruct.PLL.PLLSource = RCC_PLLSOURCE_HSE;
  RCC_OscInitStruct.PLL.PLLM = 8;
  RCC_OscInitStruct.PLL.PLLN = 336;
  RCC_OscInitStruct.PLL.PLLP = RCC_PLLP_DIV2;
  RCC_OscInitStruct.PLL.PLLQ = 7;
  if (HAL_RCC_OscConfig(&RCC_OscInitStruct) != HAL_OK)
  {
    Error_Handler();
  }
  /** Initializes the CPU, AHB and APB buses clocks
  */
  RCC_ClkInitStruct.ClockType = RCC_CLOCKTYPE_HCLK|RCC_CLOCKTYPE_SYSCLK
                              |RCC_CLOCKTYPE_PCLK1|RCC_CLOCKTYPE_PCLK2;
  RCC_ClkInitStruct.SYSCLKSource = RCC_SYSCLKSOURCE_PLLCLK;
  RCC_ClkInitStruct.AHBCLKDivider = RCC_SYSCLK_DIV1;
  RCC_ClkInitStruct.APB1CLKDivider = RCC_HCLK_DIV4;
  RCC_ClkInitStruct.APB2CLKDivider = RCC_HCLK_DIV2;

  if (HAL_RCC_ClockConfig(&RCC_ClkInitStruct, FLASH_LATENCY_5) != HAL_OK)
  {
    Error_Handler();
  }
}

static void MX_ADC1_Init(void)
{

  ADC_ChannelConfTypeDef sConfig = {0};

  /** Configure the global features of the ADC (Clock, Resolution, Data Alignment and number of conversion)
  */
  hadc1.Instance = ADC1;
  hadc1.Init.ClockPrescaler = ADC_CLOCK_SYNC_PCLK_DIV4;
  hadc1.Init.Resolution = ADC_RESOLUTION_12B;
  hadc1.Init.ScanConvMode = DISABLE;
  hadc1.Init.ContinuousConvMode = DISABLE;
  hadc1.Init.DiscontinuousConvMode = DISABLE;
  hadc1.Init.ExternalTrigConvEdge = ADC_EXTERNALTRIGCONVEDGE_NONE;
  hadc1.Init.ExternalTrigConv = ADC_SOFTWARE_START;
  hadc1.Init.DataAlign = ADC_DATAALIGN_RIGHT;
  hadc1.Init.NbrOfConversion = 1;
  hadc1.Init.DMAContinuousRequests = DISABLE;
  hadc1.Init.EOCSelection = ADC_EOC_SINGLE_CONV;
  if (HAL_ADC_Init(&hadc1) != HAL_OK)
  {
    Error_Handler();
  }
  /** Configure for the selected ADC regular channel its corresponding rank in the sequencer and its sample time.
  */
  sConfig.Channel = ADC_CHANNEL_9;
  sConfig.Rank = 1;
  sConfig.SamplingTime = ADC_SAMPLETIME_3CYCLES;
  if (HAL_ADC_ConfigChannel(&hadc1, &sConfig) != HAL_OK)
  {
    Error_Handler();
  }

}

static void MX_I2C2_Init(void)
{

  hi2c2.Instance = I2C2;
  hi2c2.Init.ClockSpeed = 100000;
  hi2c2.Init.DutyCycle = I2C_DUTYCYCLE_2;
  hi2c2.Init.OwnAddress1 = 0;
  hi2c2.Init.AddressingMode = I2C_ADDRESSINGMODE_7BIT;
  hi2c2.Init.DualAddressMode = I2C_DUALADDRESS_DISABLE;
  hi2c2.Init.OwnAddress2 = 0;
  hi2c2.Init.GeneralCallMode = I2C_GENERALCALL_DISABLE;
  hi2c2.Init.NoStretchMode = I2C_NOSTRETCH_DISABLE;
  if (HAL_I2C_Init(&hi2c2) != HAL_OK)
  {
    Error_Handler();
  }

}

static void MX_I2C3_Init(void)
{

  hi2c3.Instance = I2C3;
  hi2c3.Init.ClockSpeed = 100000;
  hi2c3.Init.DutyCycle = I2C_DUTYCYCLE_2;
  hi2c3.Init.OwnAddress1 = 0;
  hi2c3.Init.AddressingMode = I2C_ADDRESSINGMODE_7BIT;
  hi2c3.Init.DualAddressMode = I2C_DUALADDRESS_DISABLE;
  hi2c3.Init.OwnAddress2 = 0;
  hi2c3.Init.GeneralCallMode = I2C_GENERALCALL_DISABLE;
  hi2c3.Init.NoStretchMode = I2C_NOSTRETCH_DISABLE;
  if (HAL_I2C_Init(&hi2c3) != HAL_OK)
  {
    Error_Handler();
  }

}

static void MX_RNG_Init(void)
{

  hrng.Instance = RNG;
  if (HAL_RNG_Init(&hrng) != HAL_OK)
  {
    Error_Handler();
  }

}

static void MX_RTC_Init(void)
{

  RTC_TimeTypeDef sTime = {0};
  RTC_DateTypeDef sDate = {0};
  RTC_AlarmTypeDef sAlarm = {0};

  /** Initialize RTC Only
  */
  hrtc.Instance = RTC;
  hrtc.Init.HourFormat = RTC_HOURFORMAT_24;
  hrtc.Init.AsynchPrediv = 127;
  hrtc.Init.SynchPrediv = 255;
  hrtc.Init.OutPut = RTC_OUTPUT_DISABLE;
  hrtc.Init.OutPutPolarity = RTC_OUTPUT_POLARITY_HIGH;
  hrtc.Init.OutPutType = RTC_OUTPUT_TYPE_OPENDRAIN;
  if (HAL_RTC_Init(&hrtc) != HAL_OK)
  {
    Error_Handler();
  }

  /** Initialize RTC and set the Time and Date
  */
  sTime.Hours = 0x23;
  sTime.Minutes = 0x59;
  sTime.Seconds = 0x45;
  sTime.DayLightSaving = RTC_DAYLIGHTSAVING_NONE;
  sTime.StoreOperation = RTC_STOREOPERATION_RESET;
  if (HAL_RTC_SetTime(&hrtc, &sTime, RTC_FORMAT_BCD) != HAL_OK)
  {
    Error_Handler();
  }
  sDate.WeekDay = RTC_WEEKDAY_TUESDAY;
  sDate.Month = RTC_MONTH_DECEMBER;
  sDate.Date = 0x28;
  sDate.Year = 0x0;

  if (HAL_RTC_SetDate(&hrtc, &sDate, RTC_FORMAT_BCD) != HAL_OK)
  {
    Error_Handler();
  }
  /** Enable the Alarm A
  */
  sAlarm.AlarmTime.Hours = 0x0;
  sAlarm.AlarmTime.Minutes = 0x0;
  sAlarm.AlarmTime.Seconds = 0x10;
  sAlarm.AlarmTime.SubSeconds = 0x0;
  sAlarm.AlarmTime.DayLightSaving = RTC_DAYLIGHTSAVING_NONE;
  sAlarm.AlarmTime.StoreOperation = RTC_STOREOPERATION_RESET;
  sAlarm.AlarmMask = RTC_ALARMMASK_NONE;
  sAlarm.AlarmSubSecondMask = RTC_ALARMSUBSECONDMASK_ALL;
  sAlarm.AlarmDateWeekDaySel = RTC_ALARMDATEWEEKDAYSEL_WEEKDAY;
  sAlarm.AlarmDateWeekDay = RTC_WEEKDAY_MONDAY;
  sAlarm.Alarm = RTC_ALARM_A;
  if (HAL_RTC_SetAlarm(&hrtc, &sAlarm, RTC_FORMAT_BCD) != HAL_OK)
  {
    Error_Handler();
  }

}

static void MX_SPI1_Init(void)
{

  /* SPI1 parameter configuration*/
  hspi1.Instance = SPI1;
  hspi1.Init.Mode = SPI_MODE_MASTER;
  hspi1.Init.Direction = SPI_DIRECTION_2LINES;
  hspi1.Init.DataSize = SPI_DATASIZE_8BIT;
  hspi1.Init.CLKPolarity = SPI_POLARITY_LOW;
  hspi1.Init.CLKPhase = SPI_PHASE_1EDGE;
  hspi1.Init.NSS = SPI_NSS_SOFT;
  hspi1.Init.BaudRatePrescaler = SPI_BAUDRATEPRESCALER_32;
  hspi1.Init.FirstBit = SPI_FIRSTBIT_MSB;
  hspi1.Init.TIMode = SPI_TIMODE_DISABLE;
  hspi1.Init.CRCCalculation = SPI_CRCCALCULATION_DISABLE;
  hspi1.Init.CRCPolynomial = 10;
  if (HAL_SPI_Init(&hspi1) != HAL_OK)
  {
    Error_Handler();
  }

}

static void MX_SPI2_Init(void)
{

  /* SPI2 parameter configuration*/
  hspi2.Instance = SPI2;
  hspi2.Init.Mode = SPI_MODE_MASTER;
  hspi2.Init.Direction = SPI_DIRECTION_2LINES;
  hspi2.Init.DataSize = SPI_DATASIZE_8BIT;
  hspi2.Init.CLKPolarity = SPI_POLARITY_LOW;
  hspi2.Init.CLKPhase = SPI_PHASE_1EDGE;
  hspi2.Init.NSS = SPI_NSS_SOFT;
  hspi2.Init.BaudRatePrescaler = SPI_BAUDRATEPRESCALER_2;
  hspi2.Init.FirstBit = SPI_FIRSTBIT_MSB;
  hspi2.Init.TIMode = SPI_TIMODE_DISABLE;
  hspi2.Init.CRCCalculation = SPI_CRCCALCULATION_DISABLE;
  hspi2.Init.CRCPolynomial = 10;
  if (HAL_SPI_Init(&hspi2) != HAL_OK)
  {
    Error_Handler();
  }

}

static void MX_TIM1_Init(void)
{

  TIM_ClockConfigTypeDef sClockSourceConfig = {0};
  TIM_MasterConfigTypeDef sMasterConfig = {0};

  htim1.Instance = TIM1;
  htim1.Init.Prescaler = 16800-1;
  htim1.Init.CounterMode = TIM_COUNTERMODE_UP;
  htim1.Init.Period = 10000;
  htim1.Init.ClockDivision = TIM_CLOCKDIVISION_DIV1;
  htim1.Init.RepetitionCounter = 0;
  htim1.Init.AutoReloadPreload = TIM_AUTORELOAD_PRELOAD_DISABLE;
  if (HAL_TIM_Base_Init(&htim1) != HAL_OK)
  {
    Error_Handler();
  }
  sClockSourceConfig.ClockSource = TIM_CLOCKSOURCE_INTERNAL;
  if (HAL_TIM_ConfigClockSource(&htim1, &sClockSourceConfig) != HAL_OK)
  {
    Error_Handler();
  }
  sMasterConfig.MasterOutputTrigger = TIM_TRGO_UPDATE;
  sMasterConfig.MasterSlaveMode = TIM_MASTERSLAVEMODE_DISABLE;
  if (HAL_TIMEx_MasterConfigSynchronization(&htim1, &sMasterConfig) != HAL_OK)
  {
    Error_Handler();
  }

}

static void MX_TIM2_Init(void)
{

  TIM_ClockConfigTypeDef sClockSourceConfig = {0};
  TIM_MasterConfigTypeDef sMasterConfig = {0};

  htim2.Instance = TIM2;
  htim2.Init.Prescaler = 10;
  htim2.Init.CounterMode = TIM_COUNTERMODE_UP;
  htim2.Init.Period = 10;
  htim2.Init.ClockDivision = TIM_CLOCKDIVISION_DIV1;
  htim2.Init.AutoReloadPreload = TIM_AUTORELOAD_PRELOAD_DISABLE;
  if (HAL_TIM_Base_Init(&htim2) != HAL_OK)
  {
    Error_Handler();
  }
  sClockSourceConfig.ClockSource = TIM_CLOCKSOURCE_INTERNAL;
  if (HAL_TIM_ConfigClockSource(&htim2, &sClockSourceConfig) != HAL_OK)
  {
    Error_Handler();
  }
  sMasterConfig.MasterOutputTrigger = TIM_TRGO_RESET;
  sMasterConfig.MasterSlaveMode = TIM_MASTERSLAVEMODE_DISABLE;
  if (HAL_TIMEx_MasterConfigSynchronization(&htim2, &sMasterConfig) != HAL_OK)
  {
    Error_Handler();
  }

}

static void MX_TIM3_Init(void)
{

  TIM_ClockConfigTypeDef sClockSourceConfig = {0};
  TIM_MasterConfigTypeDef sMasterConfig = {0};

  htim3.Instance = TIM3;
  htim3.Init.Prescaler = 839;
  htim3.Init.CounterMode = TIM_COUNTERMODE_UP;
  htim3.Init.Period = 10;
  htim3.Init.ClockDivision = TIM_CLOCKDIVISION_DIV1;
  htim3.Init.AutoReloadPreload = TIM_AUTORELOAD_PRELOAD_ENABLE;
  if (HAL_TIM_Base_Init(&htim3) != HAL_OK)
  {
    Error_Handler();
  }
  sClockSourceConfig.ClockSource = TIM_CLOCKSOURCE_INTERNAL;
  if (HAL_TIM_ConfigClockSource(&htim3, &sClockSourceConfig) != HAL_OK)
  {
    Error_Handler();
  }
  sMasterConfig.MasterOutputTrigger = TIM_TRGO_RESET;
  sMasterConfig.MasterSlaveMode = TIM_MASTERSLAVEMODE_DISABLE;
  if (HAL_TIMEx_MasterConfigSynchronization(&htim3, &sMasterConfig) != HAL_OK)
  {
    Error_Handler();
  }

}

static void MX_TIM10_Init(void)
{

  htim10.Instance = TIM10;
  htim10.Init.Prescaler = 168-1;
  htim10.Init.CounterMode = TIM_COUNTERMODE_UP;
  htim10.Init.Period = 10-1;
  htim10.Init.ClockDivision = TIM_CLOCKDIVISION_DIV1;
  htim10.Init.AutoReloadPreload = TIM_AUTORELOAD_PRELOAD_ENABLE;
  if (HAL_TIM_Base_Init(&htim10) != HAL_OK)
  {
    Error_Handler();
  }

}

static void MX_DMA_Init(void)
{

  /* DMA controller clock enable */
  __HAL_RCC_DMA1_CLK_ENABLE();

  /* DMA interrupt init */
  /* DMA1_Stream4_IRQn interrupt configuration */
  HAL_NVIC_SetPriority(DMA1_Stream4_IRQn, 5, 0);
  HAL_NVIC_EnableIRQ(DMA1_Stream4_IRQn);

}

static void MX_GPIO_Init(void)
{
  GPIO_InitTypeDef GPIO_InitStruct = {0};

  /* GPIO Ports Clock Enable */
  __HAL_RCC_GPIOE_CLK_ENABLE();
  __HAL_RCC_GPIOC_CLK_ENABLE();
  __HAL_RCC_GPIOH_CLK_ENABLE();
  __HAL_RCC_GPIOA_CLK_ENABLE();
  __HAL_RCC_GPIOB_CLK_ENABLE();
  __HAL_RCC_GPIOD_CLK_ENABLE();

  /*Configure GPIO pin Output Level */
  HAL_GPIO_WritePin(GPIOE, T_MOSI_Pin|CS_I2C_SPI_Pin|CS_LCD_Pin|RESET_LCD_Pin
                          |DC_LCD_Pin, GPIO_PIN_RESET);

  /*Configure GPIO pin Output Level */
  HAL_GPIO_WritePin(OTG_FS_PowerSwitchOn_GPIO_Port, OTG_FS_PowerSwitchOn_Pin, GPIO_PIN_SET);

  /*Configure GPIO pin Output Level */
  HAL_GPIO_WritePin(GPIOC, AM2302_Pin|CS_microSD_Pin, GPIO_PIN_RESET);

  /*Configure GPIO pin Output Level */
  HAL_GPIO_WritePin(GPIOD, LD4_Pin|LD3_Pin|LD5_Pin|LD6_Pin
                          |Audio_RST_Pin, GPIO_PIN_RESET);

  /*Configure GPIO pin Output Level */
  HAL_GPIO_WritePin(GPIOB, T_CLK_Pin|T_CS_Pin, GPIO_PIN_RESET);

  /*Configure GPIO pins : T_MOSI_Pin CS_I2C_SPI_Pin CS_LCD_Pin */
  GPIO_InitStruct.Pin = T_MOSI_Pin|CS_I2C_SPI_Pin|CS_LCD_Pin;
  GPIO_InitStruct.Mode = GPIO_MODE_OUTPUT_PP;
  GPIO_InitStruct.Pull = GPIO_NOPULL;
  GPIO_InitStruct.Speed = GPIO_SPEED_FREQ_LOW;
  HAL_GPIO_Init(GPIOE, &GPIO_InitStruct);

  /*Configure GPIO pins : RESET_LCD_Pin DC_LCD_Pin */
  GPIO_InitStruct.Pin = RESET_LCD_Pin|DC_LCD_Pin;
  GPIO_InitStruct.Mode = GPIO_MODE_OUTPUT_PP;
  GPIO_InitStruct.Pull = GPIO_NOPULL;
  GPIO_InitStruct.Speed = GPIO_SPEED_FREQ_VERY_HIGH;
  HAL_GPIO_Init(GPIOE, &GPIO_InitStruct);

  /*Configure GPIO pin : T_IRQ_Pin */
  GPIO_InitStruct.Pin = T_IRQ_Pin;
  GPIO_InitStruct.Mode = GPIO_MODE_INPUT;
  GPIO_InitStruct.Pull = GPIO_NOPULL;
  HAL_GPIO_Init(T_IRQ_GPIO_Port, &GPIO_InitStruct);

  /*Configure GPIO pins : OTG_FS_PowerSwitchOn_Pin AM2302_Pin */
  GPIO_InitStruct.Pin = OTG_FS_PowerSwitchOn_Pin|AM2302_Pin;
  GPIO_InitStruct.Mode = GPIO_MODE_OUTPUT_PP;
  GPIO_InitStruct.Pull = GPIO_NOPULL;
  GPIO_InitStruct.Speed = GPIO_SPEED_FREQ_LOW;
  HAL_GPIO_Init(GPIOC, &GPIO_InitStruct);

  /*Configure GPIO pin : PDM_OUT_Pin */
  GPIO_InitStruct.Pin = PDM_OUT_Pin;
  GPIO_InitStruct.Mode = GPIO_MODE_AF_PP;
  GPIO_InitStruct.Pull = GPIO_NOPULL;
  GPIO_InitStruct.Speed = GPIO_SPEED_FREQ_LOW;
  GPIO_InitStruct.Alternate = GPIO_AF5_SPI2;
  HAL_GPIO_Init(PDM_OUT_GPIO_Port, &GPIO_InitStruct);

  /*Configure GPIO pin : B1_Pin */
  GPIO_InitStruct.Pin = B1_Pin;
  GPIO_InitStruct.Mode = GPIO_MODE_EVT_RISING;
  GPIO_InitStruct.Pull = GPIO_NOPULL;
  HAL_GPIO_Init(B1_GPIO_Port, &GPIO_InitStruct);

  /*Configure GPIO pin : I2S3_WS_Pin */
  GPIO_InitStruct.Pin = I2S3_WS_Pin;
  GPIO_InitStruct.Mode = GPIO_MODE_AF_PP;
  GPIO_InitStruct.Pull = GPIO_NOPULL;
  GPIO_InitStruct.Speed = GPIO_SPEED_FREQ_LOW;
  GPIO_InitStruct.Alternate = GPIO_AF6_SPI3;
  HAL_GPIO_Init(I2S3_WS_GPIO_Port, &GPIO_InitStruct);

  /*Configure GPIO pin : BOOT1_Pin */
  GPIO_InitStruct.Pin = BOOT1_Pin;
  GPIO_InitStruct.Mode = GPIO_MODE_INPUT;
  GPIO_InitStruct.Pull = GPIO_NOPULL;
  HAL_GPIO_Init(BOOT1_GPIO_Port, &GPIO_InitStruct);

  /*Configure GPIO pins : LD4_Pin LD3_Pin LD5_Pin LD6_Pin
                           Audio_RST_Pin */
  GPIO_InitStruct.Pin = LD4_Pin|LD3_Pin|LD5_Pin|LD6_Pin
                          |Audio_RST_Pin;
  GPIO_InitStruct.Mode = GPIO_MODE_OUTPUT_PP;
  GPIO_InitStruct.Pull = GPIO_NOPULL;
  GPIO_InitStruct.Speed = GPIO_SPEED_FREQ_LOW;
  HAL_GPIO_Init(GPIOD, &GPIO_InitStruct);

  /*Configure GPIO pin : CS_microSD_Pin */
  GPIO_InitStruct.Pin = CS_microSD_Pin;
  GPIO_InitStruct.Mode = GPIO_MODE_OUTPUT_PP;
  GPIO_InitStruct.Pull = GPIO_NOPULL;
  GPIO_InitStruct.Speed = GPIO_SPEED_FREQ_HIGH;
  HAL_GPIO_Init(CS_microSD_GPIO_Port, &GPIO_InitStruct);

  /*Configure GPIO pins : I2S3_MCK_Pin I2S3_SCK_Pin I2S3_SD_Pin */
  GPIO_InitStruct.Pin = I2S3_MCK_Pin|I2S3_SCK_Pin|I2S3_SD_Pin;
  GPIO_InitStruct.Mode = GPIO_MODE_AF_PP;
  GPIO_InitStruct.Pull = GPIO_NOPULL;
  GPIO_InitStruct.Speed = GPIO_SPEED_FREQ_LOW;
  GPIO_InitStruct.Alternate = GPIO_AF6_SPI3;
  HAL_GPIO_Init(GPIOC, &GPIO_InitStruct);

  /*Configure GPIO pin : OTG_FS_OverCurrent_Pin */
  GPIO_InitStruct.Pin = OTG_FS_OverCurrent_Pin;
  GPIO_InitStruct.Mode = GPIO_MODE_INPUT;
  GPIO_InitStruct.Pull = GPIO_NOPULL;
  HAL_GPIO_Init(OTG_FS_OverCurrent_GPIO_Port, &GPIO_InitStruct);

  /*Configure GPIO pins : Audio_SCL_Pin Audio_SDA_Pin */
  GPIO_InitStruct.Pin = Audio_SCL_Pin|Audio_SDA_Pin;
  GPIO_InitStruct.Mode = GPIO_MODE_AF_OD;
  GPIO_InitStruct.Pull = GPIO_PULLUP;
  GPIO_InitStruct.Speed = GPIO_SPEED_FREQ_LOW;
  GPIO_InitStruct.Alternate = GPIO_AF4_I2C1;
  HAL_GPIO_Init(GPIOB, &GPIO_InitStruct);

  /*Configure GPIO pins : T_CLK_Pin T_CS_Pin */
  GPIO_InitStruct.Pin = T_CLK_Pin|T_CS_Pin;
  GPIO_InitStruct.Mode = GPIO_MODE_OUTPUT_PP;
  GPIO_InitStruct.Pull = GPIO_NOPULL;
  GPIO_InitStruct.Speed = GPIO_SPEED_FREQ_VERY_HIGH;
  HAL_GPIO_Init(GPIOB, &GPIO_InitStruct);

  /*Configure GPIO pin : T_MISO_Pin */
  GPIO_InitStruct.Pin = T_MISO_Pin;
  GPIO_InitStruct.Mode = GPIO_MODE_INPUT;
  GPIO_InitStruct.Pull = GPIO_NOPULL;
  HAL_GPIO_Init(T_MISO_GPIO_Port, &GPIO_InitStruct);

  /*Configure GPIO pin : MEMS_INT2_Pin */
  GPIO_InitStruct.Pin = MEMS_INT2_Pin;
  GPIO_InitStruct.Mode = GPIO_MODE_EVT_RISING;
  GPIO_InitStruct.Pull = GPIO_NOPULL;
  HAL_GPIO_Init(MEMS_INT2_GPIO_Port, &GPIO_InitStruct);

}

void StartDefaultTask(void *argument)
{
  /* init code for USB_DEVICE */
  MX_USB_DEVICE_Init();
  /* USER CODE BEGIN 5 */
  /* Infinite loop */
  for(;;)
  {
	  osDelay(10);
  }
  /* USER CODE END 5 */
}

void Start_RTC(void *argument)
{
  /* USER CODE BEGIN Start_RTC */
  /* Infinite loop */
	// Task every seconds blink blue LED and send data in virtual com port.
		// Set up RTC
		/*	README <<<<<<<<<<<<<<<<<<<<<<<<<<<<<<
		 * STM32IDE  automatically generated setup code and fill in RTC structure fields seconds, minutes,
		 * hours and date. So, for avoid rewriting time, you need comment automated generated code.
		 *
		 * RTC needs BATTERY for count time when external power will be removed.
		 * For STM32F407 discovery dev board needs remove R26, and connect battery to VBAT (near R26).
		 * Also, need solder the LF Crystal and two capacitors.
		 */

		// 1. Set time
		  RTC_TimeTypeDef sTime = {0};
	//	  sTime.Hours = 9;
	//	  sTime.Minutes = 33;
	//	  sTime.Seconds = 00;
	//	  HAL_RTC_SetTime(&hrtc, &sTime, RTC_FORMAT_BIN);
		  // Set date

		  RTC_DateTypeDef sDate = {0};
	//	  sDate.Date = 29;
	//	  sDate.Month = RTC_MONTH_DECEMBER;
	//	  sDate.WeekDay = RTC_WEEKDAY_WEDNESDAY;
	//	  sDate.Year = 21;
	//	  HAL_RTC_SetDate(&hrtc, &sDate, RTC_FORMAT_BIN);
		  /////////////////////////////////////////////////////////////////////

	QUEUE_t msg;												// Make a queue

	char buff[50] = {0};
	char buf[5] = {0};
	char str_end_of_line[4] = {'\r','\n','\0'};

	static uint8_t i = 1;
	for(;;)
	{
		// Blue LED blink//
		HAL_GPIO_WritePin(GPIOD, LD6_Pin, GPIO_PIN_SET);
		osDelay(100);
		HAL_GPIO_WritePin(GPIOD, LD6_Pin, GPIO_PIN_RESET);
		osDelay(900);

		// RTC part
		HAL_RTC_GetTime(&hrtc, &sTime, RTC_FORMAT_BIN);						// Get time (write in sDime struct)
		HAL_RTC_GetDate(&hrtc, &sDate, RTC_FORMAT_BIN);						// Get data (write in sDime struct)

		memset(msg.Buf, 0, sizeof(msg.Buf));								// Fill in buff '\0'
		memset(buff, 0, sizeof(buff));

		strcat(msg.Buf, "RTC DATA AND TIME >>>>>>>    " );

		// Date
		itoa(sDate.Year, buf, 10);
		strcat(msg.Buf, buf);

		itoa(sDate.Month, buf, 10);
		strcat(msg.Buf, "-");
		strcat(msg.Buf, buf);

		itoa(sDate.Date, buf, 10);
		strcat(msg.Buf, "-");
		strcat(msg.Buf, buf);

		strcat(msg.Buf, " | ");

		// Time
		itoa(sTime.Hours, buf, 10);
		strcat(msg.Buf, buf);

		itoa(sTime.Minutes, buf, 10);
		strcat(msg.Buf, ":");
		strcat(msg.Buf, buf);

		itoa(sTime.Seconds, buf, 10);
		strcat(msg.Buf, ":");
		strcat(msg.Buf, buf);

		strcat(msg.Buf, str_end_of_line);
		osMessageQueuePut(UARTQueueHandle, &msg, 0, osWaitForever);					// Write data on queue (In will print on StartUART_Task task)
	}
  /* USER CODE END Start_RTC */
}

void Start_Show_Resources(void *argument)
{
  /* USER CODE BEGIN Start_Show_Resources */
  /* Infinite loop */
  for(;;)
  {
	  osDelay(5000);												// Every 5 second task management will print data

	  char str_end_of_line[3] = {'\r','\n'};
	  char str_sig = '-';
	  char buff[10] = {0};

	  QUEUE_t msg;												// Make a queue
	  memset(msg.Buf, 0, sizeof(msg.Buf));						// Fill in buff '\0'
	  strcat(msg.Buf, ">>>>> Free heap memory: ");				// Add string to another (Total heap)

	  freemem = xPortGetFreeHeapSize();							// Function return how many free memory.
	  itoa(freemem, buff, 10);
	  strcat(msg.Buf, buff);
	  strcat(msg.Buf, str_end_of_line);

	  // add a hat
	  strcat(msg.Buf, "| TASK NAME  | STATUS | PRIOR | STACK | NUM |\n\r\0");

	  vTaskList(str_management_memory_str);						// Fill in str_management_memory_str array management task information

	  // Finding the  end of string
	  uint16_t buffer_size = 0;
	  while(msg.Buf[buffer_size] != '\0')
	  {
	  	buffer_size ++;
	  }

	  // Add str_management_memory_str to queue string
	  int i = 0;
	  for(i = 0; str_management_memory_str[i] != '\0'; i++)
	  {
	  	// add data to queue
	  	msg.Buf[buffer_size + i] = str_management_memory_str[i];
	  }

	  // add a hat
	  char str_line[] = {"-----------------------\n\r"};
	  char str_head_2[] = {"| TASK NAME | ABS TIME | TASK TIME% |\n\r"};
	  strcat(msg.Buf, str_line);
	  strcat(msg.Buf, str_head_2);

	  memset(str_management_memory_str, 0, sizeof(str_management_memory_str));	// Clean buffer

	  vTaskGetRunTimeStats(str_management_memory_str);							// Function return how much time all functions running.

	  buffer_size = buffer_size + i + (sizeof(str_line)-1) + (sizeof(str_head_2)-1);
	  for(i = 0; str_management_memory_str[i] != '\0'; i++)
	  {
	  	// add data to queue
	  	msg.Buf[buffer_size + i] = str_management_memory_str[i];
	  }
	  strcat(msg.Buf, "#########################################\n\r");

	  osMessageQueuePut(UARTQueueHandle, &msg, 0, osWaitForever);					// Write data on queue (In will print on StartUART_Task task)
  }
  /* USER CODE END Start_Show_Resources */
}

void Start_UART_Task(void *argument)
{
  /* USER CODE BEGIN Start_UART_Task */
  /* Infinite loop */
  QUEUE_t msg;
  for(;;)
  {
	// osMessageQueueGet waiting data on a queue (If data are in queue so print it)
	osMessageQueueGet(UARTQueueHandle, &msg, 0, osWaitForever);			// Write for data on queue
	// Counting how many characters will be transmitted
	uint16_t buffer_size = 0;
	while(msg.Buf[buffer_size] != '\0')
	{
		buffer_size ++;
	}
	// Transmit over virtual comport
	CDC_Transmit_FS(msg.Buf, buffer_size);						// Transmit data over virtual comport
    osDelay(1);
  }
  /* USER CODE END Start_UART_Task */
}

void Start_bme280(void *argument)
{
  /* USER CODE BEGIN Start_bme280 */
  /* Infinite loop */

	//QUEUE_t msg;												// Make a queue

	BME280QUEUE bme280_meg;
	//memset(msg.Buf, 0, sizeof(msg.Buf));						// Fill in buff '\0'

	uint16_t STATUS=0;
	uint16_t addres_device = 0x76;  		 	// BME280
	uint16_t id_addr = 0xD0;
	uint8_t id = 96;							// in hex form
	uint8_t buff=0;        						// Return 0x96 -> Dec 60

	// For debug
	STATUS = HAL_I2C_Mem_Read(&hi2c3, addres_device<<1, id_addr, 1, &buff, 1, 1000);
	if((buff == id) && (STATUS == 0))
	{
		// BME280 founded
	}
	else
	{
		// Error !!! BME280 didn't found
	}

	// Init BME280
	dev.dev_id = BME280_I2C_ADDR_PRIM;
	dev.intf = BME280_I2C_INTF;
	dev.read = user_i2c_read;
	dev.write = user_i2c_write;
	dev.delay_ms = user_delay_ms;

	rslt = bme280_init(&dev);

	dev.settings.osr_h = BME280_OVERSAMPLING_1X;
	dev.settings.osr_p = BME280_OVERSAMPLING_16X;
	dev.settings.osr_t = BME280_OVERSAMPLING_2X;
	dev.settings.filter = BME280_FILTER_COEFF_16;
	rslt = bme280_set_sensor_settings(BME280_OSR_PRESS_SEL | BME280_OSR_TEMP_SEL | BME280_OSR_HUM_SEL | BME280_FILTER_SEL, &dev);

	rslt = bme280_set_sensor_mode(BME280_NORMAL_MODE, &dev);

	dev.delay_ms(40);

  for(;;)
  {
	  osDelay(1000);

	  char str_t_h_and_p[60] = {0};
	  char str_thp_buffer[12] = {0};

	//  memset(msg.Buf, 0, sizeof(msg.Buf));								// Fill in buff '\0'
	  memset(bme280_meg.bme280_temperature_and_humidity, 0, sizeof(bme280_meg.bme280_temperature_and_humidity));								// Fill in buff '\0'

	  rslt = bme280_get_sensor_data(BME280_ALL, &comp_data, &dev);		// Get data from sensor

	  if(rslt == BME280_OK)
	  {
	  		// Save data variables
	  		int BME280_temperature = comp_data.temperature;
	  		int BME280_humidity = comp_data.humidity;
	  		int BME280_preasure = comp_data.pressure;

	  		// Write T, H and P in str_t_h_and_p buffer
	  		// Write TEMPERATURE
//	  		strcat(str_t_h_and_p, "      BME280: \n\r");
	  		strcat(str_t_h_and_p, "T");
	  		sprintf(str_thp_buffer, "%d", BME280_temperature);
	  		strcat(str_t_h_and_p, str_thp_buffer);
	  		strcat(str_t_h_and_p, "C ");

	  		// Write HUMIDYTY
	  		// memset(str_thp_buffer, 0, sizeof(str_thp_buffer));
	  		strcat(str_t_h_and_p, "H");
	  		sprintf(str_thp_buffer, "%d", BME280_humidity);
	  		strcat(str_t_h_and_p, str_thp_buffer);
	  		strcat(str_t_h_and_p, "% ");

	  		// Write PRERASURE
	  		//memset(str_thp_buffer, 0, sizeof(str_thp_buffer));
	  		strcat(str_t_h_and_p, "P");
	  		sprintf(str_thp_buffer, "%d", BME280_preasure);
	  		strcat(str_t_h_and_p, str_thp_buffer);
	  		//strcat(str_t_h_and_p, " mm\n\r\0");

//	  		strcat(msg.Buf, str_t_h_and_p);										//	Write main buffer with data in queue
//	  		osMessageQueuePut(UARTQueueHandle, &msg, 0, osWaitForever);			// Write data on queue (In will print on StartUART_Task task)

	  		strcat(bme280_meg.bme280_temperature_and_humidity, str_t_h_and_p);
	  		osMessageQueuePut(BME280_QueueHandle, &bme280_meg, 0, osWaitForever);
	  }
	  else
	  {
		  strcat(str_t_h_and_p, "ERROR!!!");
		  osMessageQueuePut(BME280_QueueHandle, &bme280_meg, 0, osWaitForever);			// Write data on queue (In will print on StartUART_Task task)

//		  strcat(bme280_meg.bme280_temperature_and_humidity, "ERROR");
//		  osMessageQueuePut(BME280_QueueHandle, &bme280_meg, 0, osWaitForever);
	  }

  }
  /* USER CODE END Start_bme280 */
}

void Start_AM2302(void *argument)
{
  /* USER CODE BEGIN Start_AM2302 */
  /* Infinite loop */
	QUEUE_t msg;												// Make a queue
	memset(msg.Buf, 0, sizeof(msg.Buf));						// Fill in buff '\0'

	GPIOC->MODER |= GPIO_MODER_MODER1_0;            // Output mode GPIOC0
	GPIOC->OTYPER &= ~GPIO_OTYPER_OT_1;             // Push-pull mode
	GPIOC->OSPEEDR |= GPIO_OSPEEDER_OSPEEDR0_1;     // Speed
	GPIOC->ODR ^= 0x02; 							// set GPIOC pin 1 on high
	osDelay(2000);									// First init must be 2 seconds delay

  for(;;)
  {
	  osDelay(3500);			// Measure every 3 seconds
	  //----------------------------------------------------------------------------------------
	  /*
	   * Function make us delay
	   */
//	  __STATIC_INLINE void DelayMicro(__IO uint32_t micros)
//	  {
//	  	uint32_t test_micros = SystemCoreClock;
//	  	micros *= (SystemCoreClock / 100000) /84;
//	  	while (micros--);
//	  }

	  	//  function must use less than one time per 2-3 seconds.
	  /* Init work with sensor:
	   *
	   * From microcontroller
	   * 						            From sensor
	   * 	   Low 10 msec	      High 39 us|	80us Pull down     80us Pull up 	Start Receive data from sensor
	   * ____                     _______	|					 __________________
	   * 	   \	   	           /	   \|					/				   \
	   * 	   	\_________________/			\__________________/		 			\_______
	   *
	   * Receive '0' Bit
	   *     Low 50 us    High 26 - 28 us
	   * __                ___________
	   * 	 \			    /			\
	   * 	  \____________/			 \_
	   *
	   * Receive '1' Bit
	   *     Low 50 us             High 70 us
	   * __                ________________________
	   * 	 \			    /				         \
	   * 	  \____________/			              \_
	   */

	  	bool get_data_status = false;
	  	int j = 0;   							// Counter bytes
	  	int i = 0;								// Counter bits
	  	uint8_t data[4] = {0};					// Buffer for incoming data from sensor
	  	float temper, hum;						// Buffer variables

	  	// Init GPIO like output
	  	GPIOC->MODER |= GPIO_MODER_MODER1_0;            // Output mode GPIOC0
	  	GPIOC->OTYPER &= ~GPIO_OTYPER_OT_1;             // Push-pull mode
	  	GPIOC->OSPEEDR |= GPIO_OSPEEDER_OSPEEDR0_1;     // Speed

	  	GPIOC->ODR &= ~0x02;		// Low level
	  	osDelay(18);
	  	GPIOC->ODR ^= 0x02;			// High level
	  	delay_us(40);

	  	// Make input pin C1
	  	GPIOC->MODER &= ~0x04;  	// Set Pin C1 Input   (MODER GPIOC_1 Must be 00)
	  	GPIOC->PUPDR &= ~0x04;		// Set Pin C1 Pull up

	  	if(GPIOC->IDR & GPIO_IDR_ID1)		// Sensor must pull down
	  	{
	  		get_data_status = false; 					// Error. Sensor not response
	  	}
	  	else
	  	{
	  		get_data_status = true;
	  	}

	  	delay_us(80);

	  	if(!(GPIOC->IDR & GPIO_IDR_ID1))  	// Sensor must pull up
	  	{
	  		get_data_status = false; 					// Error. Sensor not response
	  	}
	  	else
	  	{
	  		get_data_status = true;
	  	}
	  	delay_us(80);

	  	if(get_data_status == true)
	  	{
	  		for(j = 0; j <5; j++)							// Reading 5 bytes
	  		{
	  			data[4-j] = 0;
	  			for(i = 0; i < 8; i++)						// Reading 8 bits
	  			{
	  				while(!(GPIOC->IDR & GPIO_IDR_ID1));	// While signal is "0"
	  				delay_us(30);
	  				if(GPIOC->IDR & GPIO_IDR_ID1)			// If signal is high when wrute "1" in buffer (data[])
	  				{
	  					data[4-j] |= (1 << (7 - i));        // Shift received bite
	  				}
	  				while(GPIOC->IDR & GPIO_IDR_ID1);		// Wait end of "1" signal
	  			}
	  			get_data_status = true;										// Data was been written okay
	  		}

	  		temper = (float)((*(uint16_t*)(data+1)) & 0x3FFF) /10;
	  		if((*(uint16_t*)(data+1)) & 0x8000) temper  *= -1.0;
	  		hum = (float)(*(int16_t*)(data+3)) / 10;

	  		// Write data in queue
	  		char str_t_and_h[60] = {0};
	  		char str_t_and_h_buffer[12] = {0};

	  		memset(msg.Buf, 0, sizeof(msg.Buf));								// Fill in buff '\0'

	  		// Write T and  H P in str_t_h buffer
	  		// Write TEMPERATURE
	  		strcat(str_t_and_h, "     AM2302: \n\r");
	  		strcat(str_t_and_h, "T: ");
	  		sprintf(str_t_and_h_buffer, "%f", temper);
	  		strcat(str_t_and_h, str_t_and_h_buffer);
	  		strcat(str_t_and_h, " C\n\r");

	  		// Write HUMIDYTY
	  		memset(str_t_and_h_buffer, 0, sizeof(str_t_and_h_buffer));

	  		strcat(str_t_and_h, "H: ");
	  		sprintf(str_t_and_h_buffer, "%f", hum);
	  		strcat(str_t_and_h, str_t_and_h_buffer);
	  		strcat(str_t_and_h, " C\n\r\0");

	  		strcat(msg.Buf, str_t_and_h);										//	Write main buffer with data in queue

	  		osMessageQueuePut(UARTQueueHandle, &msg, 0, osWaitForever);			// Write data on queue (In will print on StartUART_Task task)
	  	}
	  	else
	  	{

	  		//i2c_device.AM2302_ready_status = false;
	  	}
  }

  /* USER CODE END Start_AM2302 */
}

void Start_SD_CARD(void *argument)
{
  /* USER CODE BEGIN Start_SD_CARD */
  /* Infinite loop */

	osDelay(1000);
	Mount_SD("/");

	Create_File("test_data_1.txt");
	Update_File("test_data_1.txt","\n\rStart recording\r\n");	// Add data to the end of file

	// Create folders
	Create_Dir("test_folder_1");
	Create_Dir("test_folder_2");
	Create_Dir("test_folder_3");

	Unmount_SD("/");

	static int i = 0;											// Test data for write

  for(;;)
  {
	  // Log data ewery one second
	  osDelay(1000);
	  HAL_GPIO_WritePin(GPIOD, LD3_Pin, GPIO_PIN_SET);			// LED ON

	  Mount_SD("/");

	  char data[10] = {0};
	  sprintf(data, "%d\n", i);
	  Update_File("test_data_1.txt", data);						// Add data to the end of file
	  i++;

	  Unmount_SD("/");

	  HAL_GPIO_WritePin(GPIOD, LD3_Pin, GPIO_PIN_RESET);		// LED OFF
  }
  /* USER CODE END Start_SD_CARD */
}

void Start_LCD(void *argument)
{
  /* USER CODE BEGIN Start_LCD */
  /* Infinite loop */
	BME280QUEUE bme280_meg;
	MPU6050ACCQUEUE mpu6050_acc_meg;
	MPU6050GYROQUEUE mpu6050_gyro_meg;
	MPU6050TEMPQUEUE mpu6050_temperature_meg;
	MS5611QUEUE ms6050_temperature_and_pressure_meg;
	ADCQUEUE adc_meg;

	// Init LCD
	TFT9341_ini(240, 320);
	TFT9341_SetRotation(3);
	TFT9341_SetTextColor(TFT9341_WHITE);
	TFT9341_SetBackColor(TFT9341_BLUE);
	TFT9341_FillScreen(TFT9341_BLUE);

	// Init names sensors
	TFT9341_String_DMA(2,30, "1.RTC ");
	TFT9341_String_DMA(2,45, "2.AM2302");
	TFT9341_String_DMA(2,60, "3.BME280");
	TFT9341_String_DMA(2,75, "4.MPU6050a");
	TFT9341_String_DMA(2,90, "5.MPU6050g");
	TFT9341_String_DMA(2,105, "6.MPU6050t");
	TFT9341_String_DMA(2,120, "7.L883");
	TFT9341_String_DMA(2,135, "8.MS5611");
	TFT9341_String_DMA(2,150, "8.APDS9960");
	TFT9341_String_DMA(2,165, "9.ADC");

	for(;;)
	{
		// Waiting on BME280 data in queue
		osMessageQueueGet(BME280_QueueHandle, &bme280_meg, 0, osWaitForever);
		TFT9341_String(120, 60, bme280_meg.bme280_temperature_and_humidity);

		// Waiting on MPU6050 Acc data in queue
		osMessageQueueGet(MPU6050_Acc_QueueHandle, &mpu6050_acc_meg, 0, osWaitForever);
		TFT9341_String_DMA(120,75, mpu6050_acc_meg.mpu6050_acc_x_y_z);

		// Waiting on MPU6050 Gyro data in queue
		osMessageQueueGet(MPU6050_Gyro_QueueHandle, &mpu6050_gyro_meg, 0, osWaitForever);   // ??????
		TFT9341_String_DMA(120,90, mpu6050_gyro_meg.mpu6050_gyro_x_y_z);
		if(mpu6050_gyro_meg.mpu6050_gyro_x_y_z[2] != '\0')
		{
			int gggggg =  9999;
		}

		// Waiting on MPU6050 Temperature data in queue
		osMessageQueueGet(MPU6050_Temp_QueueHandle, &mpu6050_temperature_meg, 0, osWaitForever);
		TFT9341_String_DMA(120,105, mpu6050_temperature_meg.mpu6050_temp);

		// Waiting on MS5611 temperature and pressure data in queue
		osMessageQueueGet(MS5611_mag_QueueHandle, &ms6050_temperature_and_pressure_meg, 0, osWaitForever);
		TFT9341_String_DMA(120,135, ms6050_temperature_and_pressure_meg.MS5611_mag_x_y_z_temp_and_pressure);

//		char ADC_value_and_voltage[30];
//		}ADCQUEUE;

		// ADC_QueueHandle
		// Waiting on MS5611 temperature and pressure data in queue

//		osMessageQueueGet(ADC_QueueHandle, &adc_meg, 0, osWaitForever);
//		TFT9341_String_DMA(120,165, adc_meg.ADC_value_and_voltage);

		osDelay(1000);
  }
  /* USER CODE END Start_LCD */
}

void Start_LCD_touchscreen(void *argument)
{
  /* USER CODE BEGIN Start_LCD_touchscreen */
  /* Infinite loop */
	LCDQUEUE msg;												// Make QUEUE
	memset(msg.buff, 0, sizeof(msg.buff));						// Fill in buff '\0'
	char buffer[50] = {0};

	for(;;)
  	 {
	  memset(msg.buff, 0, sizeof(msg.buff));						// Fill in buff '\0'
	  //СЕНСОР ЕКРАНУ
	  if(TP_Touchpad_Pressed() == TOUCHPAD_PRESSED)
	  {
		  strcat(buffer, "PRESED ");

		  uint16_t x_and_y[2] = {0};
		  uint8_t status_ts = TP_Read_Coordinates(x_and_y);
		  if(status_ts == TOUCHPAD_DATA_OK)
		  {
			  // Convert coordinate from uint16_t format in string format
			  // And save it in main buffer
			  char buff_x_coordinates[6] = {0};
			  char buff_y_coordinates[6] = {0};
			  char buff_coordinates[15] = {0};

			  strcat(buff_x_coordinates, "x: ");
			  itoa(x_and_y[0], buff_x_coordinates, 10);
			  strcat(buff_x_coordinates, " ");

			  strcat(buff_y_coordinates, "y: ");
			  itoa(x_and_y[1], buff_y_coordinates, 10);
			  strcat(buff_y_coordinates, " ");

			  strcat(buff_coordinates, buff_x_coordinates);
			  strcat(buff_coordinates, buff_y_coordinates);
			  strcat(buffer, buff_coordinates);
		  }
	  }
	  else
	  {
		  strcat(buffer, "NO PRESS                  ");
	  }

	  strcat(msg.buff, buffer);
	  osMessageQueuePut(LCDQueueHandle, &msg, 0, osWaitForever);  	// Write data on queue (In will print on StartUART_Task task)
	  memset(buffer, 0, sizeof(buffer));

	  osDelay(200);
    //osDelay(1);
  }
  /* USER CODE END Start_LCD_touchscreen */
}

void Start_MPU6050(void *argument)
{
  /* USER CODE BEGIN Start_MPU6050 */
  /* Infinite loop */
  MPU6050_t MPU6050;

  MPU6050ACCQUEUE msg_acc;
  MPU6050GYROQUEUE msg_gyro;
  MPU6050TEMPQUEUE msg_temp;

	//char mpu6050_gyro_x_y_z[30];

  char mpu6050_acc[20] = {0};
  char mpu6050_gyro[20] = {0};
  char mpu6050_temp[10] = {0};

  osDelay(500);

  MPU6050_Init(&hi2c2);
  osDelay(500);

  //uint8_t pissition = 0;

  for(;;)
  {
	  int i = 0;
	  uint8_t start_pissition = 1;
	  char mpu6050_buf[10] = {0};
	  memset(msg_acc.mpu6050_acc_x_y_z, 0, sizeof(msg_acc.mpu6050_acc_x_y_z));
	  memset(msg_gyro.mpu6050_gyro_x_y_z, 0, sizeof(msg_gyro.mpu6050_gyro_x_y_z));
	  memset(msg_temp.mpu6050_temp, 0, sizeof(msg_temp.mpu6050_temp));

	  MPU6050_Read_All(&hi2c2, &MPU6050);					// Writr data in MPU6050 struct

	  ////////////////// ACCELERATION
	  // X
	  sprintf(mpu6050_buf ,"%f" ,MPU6050.Ax);
	  strcat(mpu6050_acc, "X");
	  // Read only first digits
	  i = 0;
	  uint8_t j = 0;
	  do{
		  i++;
	  }while(mpu6050_acc[i] != '\0');

	  do{
		  mpu6050_acc[i] = mpu6050_buf[j];
		  i++;
		  j++;
	  }while(j <= 3);										// Read only first digits
	  memset(mpu6050_buf, 0, sizeof(mpu6050_buf));

	  // Y
	  sprintf(mpu6050_buf ,"%f" ,MPU6050.Ay);
	  strcat(mpu6050_acc, " Y");
	  // findings end of string
	  i = 0;
	  do{
		  i++;
	  }while(mpu6050_acc[i] != '\0');

	  j = 0;
	  do{
		  mpu6050_acc[i] = mpu6050_buf[j];
		  i++;
		  j++;
	  }while(j<=3);											// Read only first digits
	  memset(mpu6050_buf, 0, sizeof(mpu6050_buf));

	  // Z
	  sprintf(mpu6050_buf ,"%f" ,MPU6050.Az);
	  strcat(mpu6050_acc, " Z");
	  // findings end of string
	  i = 0;
	  do{
		  i++;
	  }while(mpu6050_acc[i] != '\0');

	  j = 0;
	  do{
	  	mpu6050_acc[i] = mpu6050_buf[j];
	  	i++;
	  	j++;
	  }while(j<=3);											// Read only first digits
	  memset(mpu6050_buf, 0, sizeof(mpu6050_buf));

	  // Write in the acc queue
	  strcat(msg_acc.mpu6050_acc_x_y_z, mpu6050_acc);
	  memset(mpu6050_acc, 0, sizeof(mpu6050_acc));
	  osMessageQueuePut(MPU6050_Acc_QueueHandle, &msg_acc, 0, osWaitForever);

	  ////////////////// GYRO
	  memset(mpu6050_gyro, 0, sizeof(mpu6050_gyro));
	  // X
	  sprintf(mpu6050_buf ,"%f" ,MPU6050.Gx);
	  strcat(mpu6050_gyro, "X");
	  // Read only first digits
	  i = 0;
	  j = 0;
	  do{
		  i++;
	  }while(mpu6050_gyro[i] != '\0');

	  do{
		 mpu6050_gyro[i] = mpu6050_buf[j];
	  	 i++;
	  	 j++;
	  }while(j <= 3);										// Read only first digits
	  memset(mpu6050_buf, 0, sizeof(mpu6050_buf));

	  // Y
	  sprintf(mpu6050_buf ,"%f" ,MPU6050.Gy);
	  strcat(mpu6050_gyro, " Y");
	  // findings end of string
	  i = 0;
	  do{
		  i++;
	  }while(mpu6050_gyro[i] != '\0');

	  j = 0;
	  do{
		  mpu6050_gyro[i] = mpu6050_buf[j];
		  i++;
		  j++;
	  }while(j<=3);											// Read only first digits
	  memset(mpu6050_buf, 0, sizeof(mpu6050_buf));

	  // Z
	  sprintf(mpu6050_buf ,"%f" ,MPU6050.Gz);
	  strcat(mpu6050_gyro, " Z");
	  // findings end of string
	  i = 0;
	  do{
		  i++;
	  }while(mpu6050_gyro[i] != '\0');

	  j = 0;
	  do{
		  mpu6050_gyro[i] = mpu6050_buf[j];
		  i++;
	  	  j++;
	  }while(j<=3);											// Read only first digits
	  memset(mpu6050_buf, 0, sizeof(mpu6050_buf));

		if(mpu6050_gyro[2] != '\0')
		{
			int gggggg =  9999;
		}

	  // Write in the acc queue
	  strcat(msg_gyro.mpu6050_gyro_x_y_z, mpu6050_gyro);
	  memset(mpu6050_gyro, 0, sizeof(mpu6050_gyro));

	  if(msg_gyro.mpu6050_gyro_x_y_z[2] != '\0')
	  {
	  			int gggggg =  9999;
	  }
	  osMessageQueuePut(MPU6050_Gyro_QueueHandle, &msg_gyro, 0, osWaitForever);

	  ////////////////// TEMPERATURE
	  sprintf(mpu6050_buf ,"%f" ,MPU6050.Temperature);
	  strcat(mpu6050_temp, "T ");
	  // Read only first digits
	  i = 0;
	  do{
	 	i++;
	  }while(mpu6050_temp[i] != '\0');

	  j = 0;
	  do{
		  mpu6050_temp[i] = mpu6050_buf[j];
	 	  i++;
	 	  j++;
	  }while(j <= 4);										// Read only first digits
	  memset(mpu6050_buf, 0, sizeof(mpu6050_buf));

	  // Write in the acc queue
	  strcat(msg_temp.mpu6050_temp, mpu6050_temp);
	  memset(mpu6050_temp, 0, sizeof(mpu6050_temp));
	  osMessageQueuePut(MPU6050_Temp_QueueHandle, &msg_temp, 0, osWaitForever);

      osDelay(1000);
  }
  /* USER CODE END Start_MPU6050 */
}

void Start_MS5611(void *argument)
{
  /* USER CODE BEGIN Start_MS5611 */
  /* Infinite loop */
	MS5611QUEUE msg_mag;

	osDelay(500);
	//ms5611_init();

	for(;;)
	{
//		ms5611_init();
		//osDelay(100);

		double temperature = 0;
		double pressure = 0;
		char ms5611_buf[30] = {0};
		char buff[20] = {0};
		uint8_t i = 0;
		memset(msg_mag.MS5611_mag_x_y_z_temp_and_pressure, 0, sizeof(msg_mag.MS5611_mag_x_y_z_temp_and_pressure));

		// Measure T and P from MS5611 sensor
		ms5611_init();
		ms5611_update();

		strcat(ms5611_buf, "T:");

		// Get data
		temperature = ms5611_get_temperature();
		pressure = ms5611_get_pressure();
		pressure = (pressure*100) / 133.3;		// Convert

		// Add temperature data in string
		sprintf(buff, "%0.1f", temperature);
		i = 0;
		do{
			i++;
		}while(ms5611_buf[i] != '\0');

		uint8_t j = 0;
		do
		{
			ms5611_buf[i] = buff[j];
			i++;
			j++;
		}while(j <= 5);
		memset(buff, 0, sizeof(buff));
		//strcat(ms5611_buf, " C");

		// Add pressure data in string
		strcat(ms5611_buf, " P:");
		sprintf(buff, "%.0f", pressure);
		i = 0;
		do{
			i++;
		}while(ms5611_buf[i] != '\0');

		j = 0;
		do
		{
			ms5611_buf[i] = buff[j];
			i++;
			j++;
		}while(buff[j] != '\0');				// Read all digits
		memset(buff, 0, sizeof(buff));
		strcat(ms5611_buf, " mm  ");

		// Write in the queue
		strcat(msg_mag.MS5611_mag_x_y_z_temp_and_pressure, ms5611_buf);
		memset(ms5611_buf, 0, sizeof(ms5611_buf));
		osMessageQueuePut(MS5611_mag_QueueHandle, &msg_mag, 0, osWaitForever);

		osDelay(500);
  }
  /* USER CODE END Start_MS5611 */
}

void Start_ADC(void *argument)
{
  /* USER CODE BEGIN Start_ADC */
  /* Infinite loop */
	//osDelay(2000);

	ADCQUEUE msg;

	HAL_ADC_Start(&hadc1);

  for(;;)
  {
	  char adc_buff[30] = {0};
	  char adc_buff_2[10] = {0};
	  memset(msg.ADC_value_and_voltage, 0, sizeof(msg.ADC_value_and_voltage));

	  HAL_ADC_Start(&hadc1);
	  HAL_ADC_PollForConversion(&hadc1, 100);
	  uint32_t adc_data = HAL_ADC_GetValue(&hadc1);
	  // Convert in voltage
	  float adc_voltage = adc_data*(3.3/4096);
	  HAL_ADC_Stop(&hadc1);

	  sprintf(adc_buff,"%d",adc_data);
	  strcat(adc_buff, "  ");
	  sprintf(adc_buff_2,"%.4f",adc_voltage);
	  strcat(adc_buff, adc_buff_2);
	  strcat(adc_buff, " V");

	  // Write in the queue
	  strcat(msg.ADC_value_and_voltage, adc_buff);
	  memset(adc_buff, 0, sizeof(adc_buff));
	  memset(adc_buff_2, 0, sizeof(adc_buff_2));
	  //osMessageQueuePut(ADCHandle , &msg, 0, osWaitForever);

	  osDelay(1000);
  }
  /* USER CODE END Start_ADC */
}

void HAL_TIM_PeriodElapsedCallback(TIM_HandleTypeDef *htim)
{
  /* USER CODE BEGIN Callback 0 */

	// Handler for generate us dalay 			( FOR AM2302 )
	if(htim->Instance == TIM10) 				//check if the interrupt comes from TIM10
	{
		if(tim_val > 0)
		{
			tim_val = tim_val - 1;
		}
		else									// For avoid overflow variable
		{
			tim_val = 0;
		}
	}

	// Handler for SD
	if(htim->Instance == TIM1) 					//check if the interrupt comes from TIM1 (Blink LED)
	{
		//HAL_GPIO_TogglePin(GPIOD, LD4_Pin);		// Green LED
	}

	// Handler for count how many time works any tasks
	if(htim->Instance == TIM3)
	{
		ulHighFreqebcyTimerTicks++;					// Update time tasks counter
	}

  /* USER CODE END Callback 0 */
  if (htim->Instance == TIM14) {
    HAL_IncTick();
  }
  /* USER CODE BEGIN Callback 1 */

	if (htim->Instance == TIM14)		// For SD works (use in fatfs_sd.c file)
	{
		if(Timer1 > 0)
		    Timer1--;

		  if(Timer2 > 0)
		    Timer2--;
	}
  /* USER CODE END Callback 1 */
}

void Error_Handler(void)
{
  __disable_irq();
  while (1)
  {
  }
}

/************************ (C) COPYRIGHT STMicroelectronics *****END OF FILE****/
